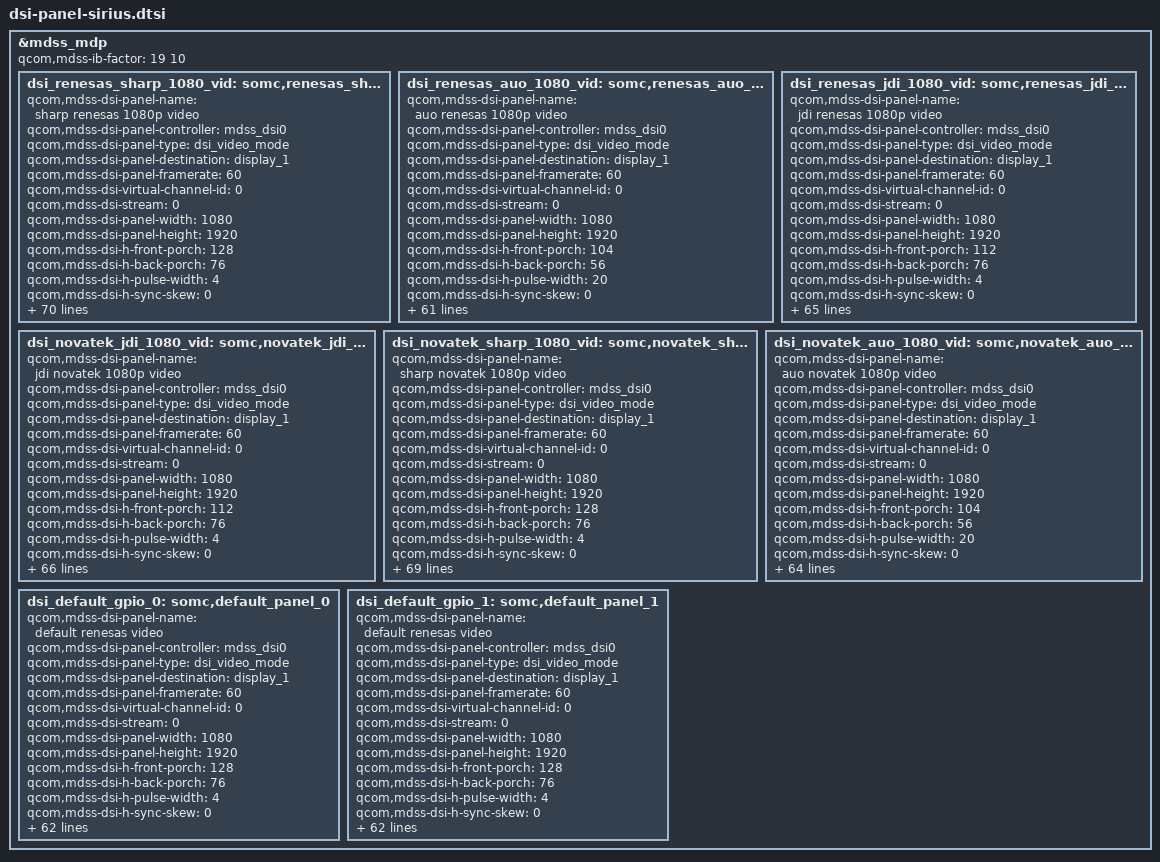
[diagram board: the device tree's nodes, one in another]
/* Copyright (c) 2012, Code Aurora Forum. All rights reserved.
 * Copyright (C) 2012-2014 Sony Mobile Communications AB.
 *
 * This program is free software; you can redistribute it and/or modify
 * it under the terms of the GNU General Public License version 2 and
 * only version 2 as published by the Free Software Foundation.
 *
 * This program is distributed in the hope that it will be useful,
 * but WITHOUT ANY WARRANTY; without even the implied warranty of
 * MERCHANTABILITY or FITNESS FOR A PARTICULAR PURPOSE.  See the
 * GNU General Public License for more details.
 */

&mdss_mdp {
	qcom,mdss-ib-factor = <19 10>;
	dsi_renesas_sharp_1080_vid: somc,renesas_sharp_1080p_panel {
		qcom,mdss-dsi-panel-name = "sharp renesas 1080p video";
		qcom,mdss-dsi-panel-controller = <&mdss_dsi0>;
		qcom,mdss-dsi-panel-type = "dsi_video_mode";
		qcom,mdss-dsi-panel-destination = "display_1";
		qcom,mdss-dsi-panel-framerate = <60>;
		qcom,mdss-dsi-virtual-channel-id = <0>;
		qcom,mdss-dsi-stream = <0>;
		qcom,mdss-dsi-panel-width = <1080>;
		qcom,mdss-dsi-panel-height = <1920>;
		qcom,mdss-dsi-h-front-porch = <128>;
		qcom,mdss-dsi-h-back-porch = <76>;
		qcom,mdss-dsi-h-pulse-width = <4>;
		qcom,mdss-dsi-h-sync-skew = <0>;
		qcom,mdss-dsi-v-back-porch = <3>;
		qcom,mdss-dsi-v-front-porch = <4>;
		qcom,mdss-dsi-v-pulse-width = <2>;
		qcom,mdss-dsi-h-left-border = <0>;
		qcom,mdss-dsi-h-right-border = <0>;
		qcom,mdss-dsi-v-top-border = <0>;
		qcom,mdss-dsi-v-bottom-border = <0>;
		qcom,mdss-dsi-bpp = <24>;
		qcom,mdss-dsi-underflow-color = <0x0>;
		qcom,mdss-dsi-border-color = <0>;
		somc,mdss-dsi-init-command = [23 01 00 00 00 00 02 B0 04
				23 01 00 00 00 00 02 00 00
				23 01 00 00 00 00 02 00 00
				23 01 00 00 00 00 02 D6 01
				29 01 00 00 00 00 03 C0 0F 0F
				29 01 00 00 00 00 03 EC 00 10
				29 01 00 00 00 00 19 C7
					05 19 22 2B 38 51 41 50 5C 64 6B 74
					0F 23 2B 32 3F 52 44 55 61 69 70 77
				29 01 00 00 00 00 19 C8
					03 18 21 2B 38 51 42 4F 5D 65 6C 74
					0D 22 2A 32 3E 52 41 54 5D 66 6D 77
				29 01 00 00 00 00 19 C9
					00 15 1E 28 36 50 42 50 5E 66 6D 74
					0A 1F 27 2F 3D 51 41 55 5E 67 6E 77
				05 01 00 00 00 00 01 11];
		qcom,mdss-dsi-on-command = [05 01 00 00 00 00 01 29];
		qcom,mdss-dsi-off-command = [05 01 00 00 14 00 01 28
				05 01 00 00 6E 00 01 10];
		qcom,mdss-dsi-on-command-state = "dsi_lp_mode";
		qcom,mdss-dsi-off-command-state = "dsi_hs_mode";

		somc,mdss-dsi-cabc-early-on-command = [39 01 00 00 00 00 03 51 0F FF
				15 01 00 00 00 00 02 53 24
				15 01 00 00 00 00 02 55 02];
		somc,mdss-dsi-cabc-late-off-command = [39 01 00 00 00 00 03 51 00 00
				15 01 00 00 00 00 02 55 00
				15 01 00 00 00 00 02 53 20];
		somc,mdss-dsi-cabc-enabled = <0>;

		qcom,mdss-dsi-h-sync-pulse = <1>;
		qcom,mdss-dsi-traffic-mode = "non_burst_sync_event";
		qcom,mdss-dsi-bllp-eof-power-mode;
		qcom,mdss-dsi-bllp-power-mode;
		qcom,mdss-dsi-lane-0-state;
		qcom,mdss-dsi-lane-1-state;
		qcom,mdss-dsi-lane-2-state;
		qcom,mdss-dsi-lane-3-state;
		qcom,mdss-dsi-panel-timings = [E6 38 26 00 68 6C 2A 3A 2C 03 04 00];
		qcom,mdss-dsi-lp11-init;
		qcom,mdss-dsi-t-clk-post = <0x02>;
		qcom,mdss-dsi-t-clk-pre = <0x2B>;
		qcom,mdss-dsi-bl-min-level = <1>;
		qcom,mdss-dsi-bl-max-level = <4095>;
		qcom,mdss-brightness-max-level = <4095>;
		qcom,mdss-dsi-dma-trigger = "trigger_sw";
		qcom,mdss-dsi-mdp-trigger = "none";
		qcom,mdss-dsi-bl-pmic-control-type = "bl_ctrl_wled";
		qcom,mdss-dsi-pan-enable-dynamic-fps;
		qcom,mdss-dsi-pan-fps-update = "dfps_suspend_resume_mode";
		qcom,cont-splash-enabled;

		somc,driver-ic = <0>;
		somc,dric-gpio = <&msmgpio 26 0>;
		somc,mul-channel-scaling = <3>;
		somc,mdss-phy-size-mm = <64 114>;
		somc,mdss-dsi-lane-config = [00 c2 ef 00 00 00 00 01 75
				00 c2 ef 00 00 00 00 01 75
				00 c2 ef 00 00 00 00 01 75
				00 c2 ef 00 00 00 00 01 75
				00 02 45 00 00 00 00 01 97];
		somc,mdss-dsi-disp-on-in-hs = <1>;
		somc,mdss-dsi-wait-time-before-on-cmd = <150>;
		somc,lcd-id = <1>;
		somc,lcd-id-adc = <0 57000>;
		somc,disp-en-on-pre = <25>;
		somc,pw-on-rst-seq = <0 60>, <1 10>;
		somc,disp-en-off-post = <50>;
		somc,pw-off-rst-b-seq = <0 10>;

		somc,mdss-dsi-pre-uv-command = [23 01 00 00 00 00 02 B0 04];
		somc,mdss-dsi-uv-command = [06 01 00 00 00 00 01 DA
					06 01 00 00 00 00 01 DB];
		somc,mdss-dsi-uv-param-type = <4>;
		somc,mdss-dsi-pcc-table-size = <73>;
		somc,mdss-dsi-pcc-table = <
			0x00 0x01 0x10 0x13 0x28 0x2B 0x8000 0x7400 0x8000
			0x00 0x02 0x14 0x17 0x28 0x2B 0x7a80 0x7400 0x7e00
			0x00 0x03 0x18 0x1B 0x28 0x2B 0x7480 0x7380 0x8000
			0x00 0x04 0x1C 0x1F 0x28 0x2B 0x7280 0x7380 0x8000
			0x00 0x05 0x20 0x23 0x28 0x2B 0x6e00 0x7400 0x8000
			0x00 0x06 0x0C 0x0F 0x24 0x27 0x7f80 0x7200 0x7c00
			0x00 0x07 0x10 0x13 0x24 0x27 0x8000 0x7400 0x7d80
			0x00 0x08 0x14 0x17 0x24 0x27 0x7d00 0x7700 0x7e00
			0x00 0x09 0x18 0x1B 0x24 0x27 0x7700 0x7600 0x8000
			0x00 0x0A 0x1C 0x1F 0x24 0x27 0x7380 0x7500 0x7c00
			0x00 0x0B 0x20 0x23 0x24 0x27 0x6f00 0x7500 0x7e80
			0x00 0x0C 0x0C 0x0F 0x20 0x23 0x7f80 0x7200 0x7900
			0x00 0x0D 0x10 0x13 0x20 0x23 0x8000 0x7400 0x7b00
			0x00 0x0E 0x14 0x17 0x20 0x23 0x7a80 0x7400 0x7b00
			0x00 0x0F 0x18 0x1B 0x20 0x23 0x7800 0x7700 0x7e80
			0x00 0x10 0x1C 0x1F 0x20 0x23 0x7780 0x7900 0x7f80
			0x00 0x11 0x20 0x23 0x20 0x23 0x7300 0x7900 0x7f00
			0x00 0x12 0x24 0x27 0x20 0x23 0x7100 0x7980 0x8000
			0x00 0x13 0x0C 0x0F 0x1C 0x1F 0x7f80 0x7200 0x7700
			0x00 0x14 0x10 0x13 0x1C 0x1F 0x7c00 0x7000 0x7580
			0x00 0x15 0x14 0x17 0x1C 0x1F 0x7f80 0x7900 0x7e00
			0x00 0x16 0x18 0x1B 0x1C 0x1F 0x7c00 0x7a00 0x7d80
			0x00 0x17 0x1C 0x1F 0x1C 0x1F 0x7900 0x7a00 0x7e00
			0x00 0x18 0x20 0x23 0x1C 0x1F 0x7600 0x7c80 0x8000
			0x00 0x19 0x24 0x27 0x1C 0x1F 0x7300 0x7c00 0x7e80
			0x00 0x1A 0x0C 0x0F 0x18 0x1B 0x8000 0x7200 0x7300
			0x00 0x1B 0x10 0x13 0x18 0x1B 0x7e80 0x7200 0x7500
			0x00 0x1C 0x14 0x17 0x18 0x1B 0x7f00 0x7900 0x7b80
			0x00 0x1D 0x18 0x1B 0x18 0x1B 0x7f00 0x7d00 0x7e00
			0x00 0x1E 0x1C 0x1F 0x18 0x1B 0x7d00 0x7d80 0x8000
			0x00 0x1F 0x20 0x23 0x18 0x1B 0x7900 0x7f00 0x8000
			0x00 0x20 0x24 0x27 0x18 0x1B 0x7780 0x8000 0x8000
			0x00 0x21 0x10 0x13 0x14 0x17 0x7f80 0x7380 0x7200
			0x00 0x22 0x14 0x17 0x14 0x17 0x7f00 0x7900 0x7900
			0x00 0x23 0x18 0x1B 0x14 0x17 0x7f00 0x7d00 0x7b80
			0xFF 0x00 0x1C 0x1F 0x14 0x17 0x8000 0x8000 0x8000
			0x00 0x24 0x20 0x23 0x14 0x17 0x7a00 0x8000 0x7e80
			0x00 0x25 0x24 0x27 0x14 0x17 0x7780 0x8000 0x7d80
			0x00 0x26 0x10 0x13 0x10 0x13 0x8000 0x7400 0x7000
			0x00 0x27 0x14 0x17 0x10 0x13 0x7f80 0x7900 0x7680
			0x00 0x28 0x18 0x1B 0x10 0x13 0x8000 0x7d80 0x7980
			0x00 0x29 0x1C 0x1F 0x10 0x13 0x8000 0x8000 0x7c00
			0x00 0x2A 0x20 0x23 0x10 0x13 0x7a00 0x8000 0x7c00
			0x00 0x2B 0x10 0x13 0x0C 0x0F 0x7f80 0x7480 0x6f00
			0x00 0x2C 0x14 0x17 0x0C 0x0F 0x7f80 0x7900 0x7400
			0x00 0x2D 0x18 0x1B 0x0C 0x0F 0x7f80 0x7d80 0x7680
			0x00 0x2E 0x1C 0x1F 0x0C 0x0F 0x8000 0x8000 0x7980
			0x01 0x00 0x00 0x09 0x32 0x3B 0x8000 0x6D00 0x8000
			0x02 0x00 0x0A 0x13 0x32 0x3B 0x7A00 0x7100 0x8000
			0x03 0x00 0x14 0x1D 0x32 0x3B 0x7400 0x7180 0x8000
			0x04 0x00 0x1E 0x27 0x32 0x3B 0x7100 0x7200 0x8000
			0x05 0x00 0x28 0x31 0x32 0x3B 0x6C80 0x7180 0x8000
			0x06 0x00 0x32 0x3B 0x32 0x3B 0x6680 0x7300 0x8000
			0x07 0x00 0x00 0x09 0x28 0x31 0x8000 0x6B80 0x7080
			0x08 0x00 0x0A 0x13 0x28 0x31 0x8000 0x7400 0x8000
			0x09 0x00 0x14 0x1D 0x28 0x31 0x7A00 0x7700 0x8000
			0x0A 0x00 0x1E 0x27 0x28 0x31 0x7600 0x7780 0x8000
			0x0B 0x00 0x28 0x31 0x28 0x31 0x6F80 0x7980 0x8000
			0x0C 0x00 0x32 0x3B 0x28 0x31 0x7080 0x7E80 0x8000
			0x0D 0x00 0x00 0x09 0x14 0x27 0x8000 0x6B00 0x6D00
			0x0E 0x00 0x0A 0x13 0x14 0x27 0x8000 0x7380 0x7480
			0xFF 0x00 0x14 0x27 0x14 0x27 0x8000 0x8000 0x8000
			0x10 0x00 0x28 0x31 0x14 0x27 0x7500 0x8000 0x7E80
			0x11 0x00 0x32 0x3B 0x14 0x27 0x7100 0x8000 0x7C80
			0x12 0x00 0x00 0x09 0x00 0x09 0x8000 0x6900 0x6500
			0x13 0x00 0x00 0x13 0x0A 0x13 0x8000 0x7300 0x6F00
			0x13 0x00 0x0A 0x13 0x00 0x09 0x8000 0x7300 0x6F00
			0x14 0x00 0x14 0x27 0x0A 0x13 0x7F00 0x8000 0x7900
			0x15 0x00 0x14 0x27 0x00 0x09 0x7E80 0x8000 0x7680
			0x16 0x00 0x28 0x31 0x0A 0x13 0x7380 0x8000 0x7600
			0x17 0x00 0x32 0x3B 0x0A 0x13 0x7080 0x8000 0x7900
			0x18 0x00 0x28 0x31 0x00 0x09 0x7A00 0x8000 0x7580
			0x19 0x00 0x32 0x3B 0x00 0x09 0x6F00 0x8000 0x7200>;
	};

	dsi_renesas_auo_1080_vid: somc,renesas_auo_1080p_panel {
		qcom,mdss-dsi-panel-name = "auo renesas 1080p video";
		qcom,mdss-dsi-panel-controller = <&mdss_dsi0>;
		qcom,mdss-dsi-panel-type = "dsi_video_mode";
		qcom,mdss-dsi-panel-destination = "display_1";
		qcom,mdss-dsi-panel-framerate = <60>;
		qcom,mdss-dsi-virtual-channel-id = <0>;
		qcom,mdss-dsi-stream = <0>;
		qcom,mdss-dsi-panel-width = <1080>;
		qcom,mdss-dsi-panel-height = <1920>;
		qcom,mdss-dsi-h-front-porch = <104>;
		qcom,mdss-dsi-h-back-porch = <56>;
		qcom,mdss-dsi-h-pulse-width = <20>;
		qcom,mdss-dsi-h-sync-skew = <0>;
		qcom,mdss-dsi-v-back-porch = <20>;
		qcom,mdss-dsi-v-front-porch = <24>;
		qcom,mdss-dsi-v-pulse-width = <10>;
		qcom,mdss-dsi-h-left-border = <0>;
		qcom,mdss-dsi-h-right-border = <0>;
		qcom,mdss-dsi-v-top-border = <0>;
		qcom,mdss-dsi-v-bottom-border = <0>;
		qcom,mdss-dsi-bpp = <24>;
		qcom,mdss-dsi-underflow-color = <0x0>;
		qcom,mdss-dsi-border-color = <0>;
		somc,mdss-dsi-init-command = [15 01 00 00 00 00 02 35 01
				29 01 00 00 00 00 02 B0 04
				29 01 00 00 00 00 08 C2 30 F7 84 1B 0C 00 00
				29 01 00 00 00 00 02 D6 01
				05 01 00 00 00 00 01 29];
		qcom,mdss-dsi-on-command = [05 01 00 00 78 00 01 11];
		qcom,mdss-dsi-off-command = [05 01 00 00 00 00 01 28
				05 01 00 00 43 00 01 10];
		qcom,mdss-dsi-on-command-state = "dsi_lp_mode";
		qcom,mdss-dsi-off-command-state = "dsi_hs_mode";
		qcom,mdss-dsi-h-sync-pulse = <1>;
		qcom,mdss-dsi-traffic-mode = "non_burst_sync_event";
		qcom,mdss-dsi-bllp-eof-power-mode;
		qcom,mdss-dsi-bllp-power-mode;
		qcom,mdss-dsi-lane-0-state;
		qcom,mdss-dsi-lane-1-state;
		qcom,mdss-dsi-lane-2-state;
		qcom,mdss-dsi-lane-3-state;
		qcom,mdss-dsi-panel-timings = [E6 38 26 00 68 6C 2A 3C 2C 03 04 00];
		qcom,mdss-dsi-t-clk-post = <0x02>;
		qcom,mdss-dsi-t-clk-pre = <0x2B>;
		qcom,mdss-dsi-bl-min-level = <1>;
		qcom,mdss-dsi-bl-max-level = <4095>;
		qcom,mdss-brightness-max-level = <4095>;
		qcom,mdss-dsi-dma-trigger = "trigger_sw";
		qcom,mdss-dsi-mdp-trigger = "none";
		qcom,mdss-dsi-bl-pmic-control-type = "bl_ctrl_wled";
		qcom,mdss-dsi-pan-enable-dynamic-fps;
		qcom,mdss-dsi-pan-fps-update = "dfps_suspend_resume_mode";
		qcom,cont-splash-enabled;

		somc,driver-ic = <0>;
		somc,dric-gpio = <&msmgpio 26 0>;
		somc,mul-channel-scaling = <3>;
		somc,mdss-phy-size-mm = <64 114>;
		somc,mdss-dsi-lane-config = [00 c2 ef 00 00 00 00 01 75
				00 c2 ef 00 00 00 00 01 75
				00 c2 ef 00 00 00 00 01 75
				00 c2 ef 00 00 00 00 01 75
				00 02 45 00 00 00 00 01 97];
		somc,mdss-dsi-disp-on-in-hs = <1>;
		somc,lcd-id = <1>;
		somc,lcd-id-adc = <215000 256000>;
		somc,pw-on-rst-seq = <1 10>, <0 1>, <1 10>;
		somc,pw-off-rst-seq = <0 0>;

		somc,mdss-dsi-pre-uv-command = [23 01 00 00 00 00 02 B0 04];
		somc,mdss-dsi-uv-command = [06 01 00 00 00 00 01 DA
					06 01 00 00 00 00 01 DC];
		somc,mdss-dsi-uv-param-type = <4>;
		somc,mdss-dsi-pcc-table-size = <73>;
		somc,mdss-dsi-pcc-table = <
			0x00 0x01 0x10 0x13 0x28 0x2B 0x8000 0x7400 0x8000
			0x00 0x02 0x14 0x17 0x28 0x2B 0x7a80 0x7400 0x7e00
			0x00 0x03 0x18 0x1B 0x28 0x2B 0x7480 0x7380 0x8000
			0x00 0x04 0x1C 0x1F 0x28 0x2B 0x7280 0x7380 0x8000
			0x00 0x05 0x20 0x23 0x28 0x2B 0x6e00 0x7400 0x8000
			0x00 0x06 0x0C 0x0F 0x24 0x27 0x7f80 0x7200 0x7c00
			0x00 0x07 0x10 0x13 0x24 0x27 0x8000 0x7400 0x7d80
			0x00 0x08 0x14 0x17 0x24 0x27 0x7d00 0x7700 0x7e00
			0x00 0x09 0x18 0x1B 0x24 0x27 0x7700 0x7600 0x8000
			0x00 0x0A 0x1C 0x1F 0x24 0x27 0x7380 0x7500 0x7c00
			0x00 0x0B 0x20 0x23 0x24 0x27 0x6f00 0x7500 0x7e80
			0x00 0x0C 0x0C 0x0F 0x20 0x23 0x7f80 0x7200 0x7900
			0x00 0x0D 0x10 0x13 0x20 0x23 0x8000 0x7400 0x7b00
			0x00 0x0E 0x14 0x17 0x20 0x23 0x7a80 0x7400 0x7b00
			0x00 0x0F 0x18 0x1B 0x20 0x23 0x7800 0x7700 0x7e80
			0x00 0x10 0x1C 0x1F 0x20 0x23 0x7780 0x7900 0x7f80
			0x00 0x11 0x20 0x23 0x20 0x23 0x7300 0x7900 0x7f00
			0x00 0x12 0x24 0x27 0x20 0x23 0x7100 0x7980 0x8000
			0x00 0x13 0x0C 0x0F 0x1C 0x1F 0x7f80 0x7200 0x7700
			0x00 0x14 0x10 0x13 0x1C 0x1F 0x7c00 0x7000 0x7580
			0x00 0x15 0x14 0x17 0x1C 0x1F 0x7f80 0x7900 0x7e00
			0x00 0x16 0x18 0x1B 0x1C 0x1F 0x7c00 0x7a00 0x7d80
			0x00 0x17 0x1C 0x1F 0x1C 0x1F 0x7900 0x7a00 0x7e00
			0x00 0x18 0x20 0x23 0x1C 0x1F 0x7600 0x7c80 0x8000
			0x00 0x19 0x24 0x27 0x1C 0x1F 0x7300 0x7c00 0x7e80
			0x00 0x1A 0x0C 0x0F 0x18 0x1B 0x8000 0x7200 0x7300
			0x00 0x1B 0x10 0x13 0x18 0x1B 0x7e80 0x7200 0x7500
			0x00 0x1C 0x14 0x17 0x18 0x1B 0x7f00 0x7900 0x7b80
			0x00 0x1D 0x18 0x1B 0x18 0x1B 0x7f00 0x7d00 0x7e00
			0x00 0x1E 0x1C 0x1F 0x18 0x1B 0x7d00 0x7d80 0x8000
			0x00 0x1F 0x20 0x23 0x18 0x1B 0x7900 0x7f00 0x8000
			0x00 0x20 0x24 0x27 0x18 0x1B 0x7780 0x8000 0x8000
			0x00 0x21 0x10 0x13 0x14 0x17 0x7f80 0x7380 0x7200
			0x00 0x22 0x14 0x17 0x14 0x17 0x7f00 0x7900 0x7900
			0x00 0x23 0x18 0x1B 0x14 0x17 0x7f00 0x7d00 0x7b80
			0xFF 0x00 0x1C 0x1F 0x14 0x17 0x8000 0x8000 0x8000
			0x00 0x24 0x20 0x23 0x14 0x17 0x7a00 0x8000 0x7e80
			0x00 0x25 0x24 0x27 0x14 0x17 0x7780 0x8000 0x7d80
			0x00 0x26 0x10 0x13 0x10 0x13 0x8000 0x7400 0x7000
			0x00 0x27 0x14 0x17 0x10 0x13 0x7f80 0x7900 0x7680
			0x00 0x28 0x18 0x1B 0x10 0x13 0x8000 0x7d80 0x7980
			0x00 0x29 0x1C 0x1F 0x10 0x13 0x8000 0x8000 0x7c00
			0x00 0x2A 0x20 0x23 0x10 0x13 0x7a00 0x8000 0x7c00
			0x00 0x2B 0x10 0x13 0x0C 0x0F 0x7f80 0x7480 0x6f00
			0x00 0x2C 0x14 0x17 0x0C 0x0F 0x7f80 0x7900 0x7400
			0x00 0x2D 0x18 0x1B 0x0C 0x0F 0x7f80 0x7d80 0x7680
			0x00 0x2E 0x1C 0x1F 0x0C 0x0F 0x8000 0x8000 0x7980
			0x01 0x00 0x00 0x09 0x32 0x3B 0x8000 0x6D00 0x8000
			0x02 0x00 0x0A 0x13 0x32 0x3B 0x7A00 0x7100 0x8000
			0x03 0x00 0x14 0x1D 0x32 0x3B 0x7400 0x7180 0x8000
			0x04 0x00 0x1E 0x27 0x32 0x3B 0x7100 0x7200 0x8000
			0x05 0x00 0x28 0x31 0x32 0x3B 0x6C80 0x7180 0x8000
			0x06 0x00 0x32 0x3B 0x32 0x3B 0x6680 0x7300 0x8000
			0x07 0x00 0x00 0x09 0x28 0x31 0x8000 0x6B80 0x7080
			0x08 0x00 0x0A 0x13 0x28 0x31 0x8000 0x7400 0x8000
			0x09 0x00 0x14 0x1D 0x28 0x31 0x7A00 0x7700 0x8000
			0x0A 0x00 0x1E 0x27 0x28 0x31 0x7600 0x7780 0x8000
			0x0B 0x00 0x28 0x31 0x28 0x31 0x6F80 0x7980 0x8000
			0x0C 0x00 0x32 0x3B 0x28 0x31 0x7080 0x7E80 0x8000
			0x0D 0x00 0x00 0x09 0x14 0x27 0x8000 0x6B00 0x6D00
			0x0E 0x00 0x0A 0x13 0x14 0x27 0x8000 0x7380 0x7480
			0xFF 0x00 0x14 0x27 0x14 0x27 0x8000 0x8000 0x8000
			0x10 0x00 0x28 0x31 0x14 0x27 0x7500 0x8000 0x7E80
			0x11 0x00 0x32 0x3B 0x14 0x27 0x7100 0x8000 0x7C80
			0x12 0x00 0x00 0x09 0x00 0x09 0x8000 0x6900 0x6500
			0x13 0x00 0x00 0x13 0x0A 0x13 0x8000 0x7300 0x6F00
			0x13 0x00 0x0A 0x13 0x00 0x09 0x8000 0x7300 0x6F00
			0x14 0x00 0x14 0x27 0x0A 0x13 0x7F00 0x8000 0x7900
			0x15 0x00 0x14 0x27 0x00 0x09 0x7E80 0x8000 0x7680
			0x16 0x00 0x28 0x31 0x0A 0x13 0x7380 0x8000 0x7600
			0x17 0x00 0x32 0x3B 0x0A 0x13 0x7080 0x8000 0x7900
			0x18 0x00 0x28 0x31 0x00 0x09 0x7A00 0x8000 0x7580
			0x19 0x00 0x32 0x3B 0x00 0x09 0x6F00 0x8000 0x7200>;
	};

	dsi_renesas_jdi_1080_vid: somc,renesas_jdi_1080p_panel {
		qcom,mdss-dsi-panel-name = "jdi renesas 1080p video";
		qcom,mdss-dsi-panel-controller = <&mdss_dsi0>;
		qcom,mdss-dsi-panel-type = "dsi_video_mode";
		qcom,mdss-dsi-panel-destination = "display_1";
		qcom,mdss-dsi-panel-framerate = <60>;
		qcom,mdss-dsi-virtual-channel-id = <0>;
		qcom,mdss-dsi-stream = <0>;
		qcom,mdss-dsi-panel-width = <1080>;
		qcom,mdss-dsi-panel-height = <1920>;
		qcom,mdss-dsi-h-front-porch = <112>;
		qcom,mdss-dsi-h-back-porch = <76>;
		qcom,mdss-dsi-h-pulse-width = <4>;
		qcom,mdss-dsi-h-sync-skew = <0>;
		qcom,mdss-dsi-v-back-porch = <4>;
		qcom,mdss-dsi-v-front-porch = <27>;
		qcom,mdss-dsi-v-pulse-width = <4>;
		qcom,mdss-dsi-h-left-border = <0>;
		qcom,mdss-dsi-h-right-border = <0>;
		qcom,mdss-dsi-v-top-border = <0>;
		qcom,mdss-dsi-v-bottom-border = <0>;
		qcom,mdss-dsi-bpp = <24>;
		qcom,mdss-dsi-underflow-color = <0x0>;
		qcom,mdss-dsi-border-color = <0>;
		somc,mdss-dsi-init-command = [05 01 00 00 05 00 01 01
				23 01 00 00 00 00 02 B0 00
				23 01 00 00 00 00 02 00 00
				23 01 00 00 00 00 02 00 00
				29 01 00 00 00 00 19 C7
					08 12 1B 24 31 48 40 52 5E 61 6A 76
					08 12 1B 24 31 48 40 52 5E 61 6A 76
				29 01 00 00 00 00 19 C8
					08 12 1B 24 31 49 41 53 5E 61 6A 76
					08 12 1B 24 31 49 41 53 5E 61 6A 76
				29 01 00 00 00 00 19 C9
					08 12 1B 24 31 47 3F 52 5E 61 6A 76
					08 12 1B 24 31 47 3F 52 5E 61 6A 76
				29 01 00 00 00 00 1B D3
					1B 33 BB CC C4 33 33 33 00 01 00 A0 D8
					A0 06 2B 33 33 22 70 02 2B 43 3D BF 99
				23 01 00 00 00 00 02 D6 01];
		qcom,mdss-dsi-on-command = [05 01 00 00 78 00 01 11
				05 01 00 00 00 00 01 29];
		qcom,mdss-dsi-off-command = [05 01 00 00 14 00 01 28
				05 01 00 00 50 00 01 10];
		qcom,mdss-dsi-on-command-state = "dsi_lp_mode";
		qcom,mdss-dsi-off-command-state = "dsi_hs_mode";
		qcom,mdss-dsi-h-sync-pulse = <1>;
		qcom,mdss-dsi-traffic-mode = "non_burst_sync_event";
		qcom,mdss-dsi-bllp-eof-power-mode;
		qcom,mdss-dsi-bllp-power-mode;
		qcom,mdss-dsi-lane-0-state;
		qcom,mdss-dsi-lane-1-state;
		qcom,mdss-dsi-lane-2-state;
		qcom,mdss-dsi-lane-3-state;
		qcom,mdss-dsi-panel-timings = [E6 38 26 00 68 6C 2A 3C 2C 03 04 00];
		qcom,mdss-dsi-lp11-init;
		qcom,mdss-dsi-t-clk-post = <0x02>;
		qcom,mdss-dsi-t-clk-pre = <0x2B>;
		qcom,mdss-dsi-bl-min-level = <1>;
		qcom,mdss-dsi-bl-max-level = <4095>;
		qcom,mdss-brightness-max-level = <4095>;
		qcom,mdss-dsi-dma-trigger = "trigger_sw";
		qcom,mdss-dsi-mdp-trigger = "none";
		qcom,mdss-dsi-bl-pmic-control-type = "bl_ctrl_wled";
		qcom,mdss-dsi-pan-enable-dynamic-fps;
		qcom,mdss-dsi-pan-fps-update = "dfps_suspend_resume_mode";
		qcom,cont-splash-enabled;

		somc,driver-ic = <0>;
		somc,dric-gpio = <&msmgpio 26 0>;
		somc,mul-channel-scaling = <3>;
		somc,mdss-phy-size-mm = <64 114>;
		somc,mdss-dsi-lane-config = [00 c2 ef 00 00 00 00 01 75
				00 c2 ef 00 00 00 00 01 75
				00 c2 ef 00 00 00 00 01 75
				00 c2 ef 00 00 00 00 01 75
				00 02 45 00 00 00 00 01 97];
		somc,mdss-dsi-disp-on-in-hs = <1>;
		somc,lcd-id = <1>;
		somc,lcd-id-adc = <353000 414000>;
		somc,disp-en-on-pre = <5>;
		somc,disp-en-on-post = <15>;
		somc,disp-en-off-post = <70>;
		somc,pw-on-rst-seq = <1 10>;
		somc,pw-off-rst-seq = <0 0>;

		somc,mdss-dsi-pre-uv-command = [23 01 00 00 00 00 02 B0 04];
		somc,mdss-dsi-uv-command = [06 01 00 00 00 00 01 DA
					06 01 00 00 00 00 01 DB];
		somc,mdss-dsi-uv-param-type = <4>;
		somc,mdss-dsi-pcc-table-size = <73>;
		somc,mdss-dsi-pcc-table = <
			0x00 0x01 0x10 0x13 0x28 0x2B 0x8000 0x7400 0x8000
			0x00 0x02 0x14 0x17 0x28 0x2B 0x7a80 0x7400 0x7e00
			0x00 0x03 0x18 0x1B 0x28 0x2B 0x7480 0x7380 0x8000
			0x00 0x04 0x1C 0x1F 0x28 0x2B 0x7280 0x7380 0x8000
			0x00 0x05 0x20 0x23 0x28 0x2B 0x6e00 0x7400 0x8000
			0x00 0x06 0x0C 0x0F 0x24 0x27 0x7f80 0x7200 0x7c00
			0x00 0x07 0x10 0x13 0x24 0x27 0x8000 0x7400 0x7d80
			0x00 0x08 0x14 0x17 0x24 0x27 0x7d00 0x7700 0x7e00
			0x00 0x09 0x18 0x1B 0x24 0x27 0x7700 0x7600 0x8000
			0x00 0x0A 0x1C 0x1F 0x24 0x27 0x7380 0x7500 0x7c00
			0x00 0x0B 0x20 0x23 0x24 0x27 0x6f00 0x7500 0x7e80
			0x00 0x0C 0x0C 0x0F 0x20 0x23 0x7f80 0x7200 0x7900
			0x00 0x0D 0x10 0x13 0x20 0x23 0x8000 0x7400 0x7b00
			0x00 0x0E 0x14 0x17 0x20 0x23 0x7a80 0x7400 0x7b00
			0x00 0x0F 0x18 0x1B 0x20 0x23 0x7800 0x7700 0x7e80
			0x00 0x10 0x1C 0x1F 0x20 0x23 0x7780 0x7900 0x7f80
			0x00 0x11 0x20 0x23 0x20 0x23 0x7300 0x7900 0x7f00
			0x00 0x12 0x24 0x27 0x20 0x23 0x7100 0x7980 0x8000
			0x00 0x13 0x0C 0x0F 0x1C 0x1F 0x7f80 0x7200 0x7700
			0x00 0x14 0x10 0x13 0x1C 0x1F 0x7c00 0x7000 0x7580
			0x00 0x15 0x14 0x17 0x1C 0x1F 0x7f80 0x7900 0x7e00
			0x00 0x16 0x18 0x1B 0x1C 0x1F 0x7c00 0x7a00 0x7d80
			0x00 0x17 0x1C 0x1F 0x1C 0x1F 0x7900 0x7a00 0x7e00
			0x00 0x18 0x20 0x23 0x1C 0x1F 0x7600 0x7c80 0x8000
			0x00 0x19 0x24 0x27 0x1C 0x1F 0x7300 0x7c00 0x7e80
			0x00 0x1A 0x0C 0x0F 0x18 0x1B 0x8000 0x7200 0x7300
			0x00 0x1B 0x10 0x13 0x18 0x1B 0x7e80 0x7200 0x7500
			0x00 0x1C 0x14 0x17 0x18 0x1B 0x7f00 0x7900 0x7b80
			0x00 0x1D 0x18 0x1B 0x18 0x1B 0x7f00 0x7d00 0x7e00
			0x00 0x1E 0x1C 0x1F 0x18 0x1B 0x7d00 0x7d80 0x8000
			0x00 0x1F 0x20 0x23 0x18 0x1B 0x7900 0x7f00 0x8000
			0x00 0x20 0x24 0x27 0x18 0x1B 0x7780 0x8000 0x8000
			0x00 0x21 0x10 0x13 0x14 0x17 0x7f80 0x7380 0x7200
			0x00 0x22 0x14 0x17 0x14 0x17 0x7f00 0x7900 0x7900
			0x00 0x23 0x18 0x1B 0x14 0x17 0x7f00 0x7d00 0x7b80
			0xFF 0x00 0x1C 0x1F 0x14 0x17 0x8000 0x8000 0x8000
			0x00 0x24 0x20 0x23 0x14 0x17 0x7a00 0x8000 0x7e80
			0x00 0x25 0x24 0x27 0x14 0x17 0x7780 0x8000 0x7d80
			0x00 0x26 0x10 0x13 0x10 0x13 0x8000 0x7400 0x7000
			0x00 0x27 0x14 0x17 0x10 0x13 0x7f80 0x7900 0x7680
			0x00 0x28 0x18 0x1B 0x10 0x13 0x8000 0x7d80 0x7980
			0x00 0x29 0x1C 0x1F 0x10 0x13 0x8000 0x8000 0x7c00
			0x00 0x2A 0x20 0x23 0x10 0x13 0x7a00 0x8000 0x7c00
			0x00 0x2B 0x10 0x13 0x0C 0x0F 0x7f80 0x7480 0x6f00
			0x00 0x2C 0x14 0x17 0x0C 0x0F 0x7f80 0x7900 0x7400
			0x00 0x2D 0x18 0x1B 0x0C 0x0F 0x7f80 0x7d80 0x7680
			0x00 0x2E 0x1C 0x1F 0x0C 0x0F 0x8000 0x8000 0x7980
			0x01 0x00 0x00 0x09 0x32 0x3B 0x8000 0x6D00 0x8000
			0x02 0x00 0x0A 0x13 0x32 0x3B 0x7A00 0x7100 0x8000
			0x03 0x00 0x14 0x1D 0x32 0x3B 0x7400 0x7180 0x8000
			0x04 0x00 0x1E 0x27 0x32 0x3B 0x7100 0x7200 0x8000
			0x05 0x00 0x28 0x31 0x32 0x3B 0x6C80 0x7180 0x8000
			0x06 0x00 0x32 0x3B 0x32 0x3B 0x6680 0x7300 0x8000
			0x07 0x00 0x00 0x09 0x28 0x31 0x8000 0x6B80 0x7080
			0x08 0x00 0x0A 0x13 0x28 0x31 0x8000 0x7400 0x8000
			0x09 0x00 0x14 0x1D 0x28 0x31 0x7A00 0x7700 0x8000
			0x0A 0x00 0x1E 0x27 0x28 0x31 0x7600 0x7780 0x8000
			0x0B 0x00 0x28 0x31 0x28 0x31 0x6F80 0x7980 0x8000
			0x0C 0x00 0x32 0x3B 0x28 0x31 0x7080 0x7E80 0x8000
			0x0D 0x00 0x00 0x09 0x14 0x27 0x8000 0x6B00 0x6D00
			0x0E 0x00 0x0A 0x13 0x14 0x27 0x8000 0x7380 0x7480
			0xFF 0x00 0x14 0x27 0x14 0x27 0x8000 0x8000 0x8000
			0x10 0x00 0x28 0x31 0x14 0x27 0x7500 0x8000 0x7E80
			0x11 0x00 0x32 0x3B 0x14 0x27 0x7100 0x8000 0x7C80
			0x12 0x00 0x00 0x09 0x00 0x09 0x8000 0x6900 0x6500
			0x13 0x00 0x00 0x13 0x0A 0x13 0x8000 0x7300 0x6F00
			0x13 0x00 0x0A 0x13 0x00 0x09 0x8000 0x7300 0x6F00
			0x14 0x00 0x14 0x27 0x0A 0x13 0x7F00 0x8000 0x7900
			0x15 0x00 0x14 0x27 0x00 0x09 0x7E80 0x8000 0x7680
			0x16 0x00 0x28 0x31 0x0A 0x13 0x7380 0x8000 0x7600
			0x17 0x00 0x32 0x3B 0x0A 0x13 0x7080 0x8000 0x7900
			0x18 0x00 0x28 0x31 0x00 0x09 0x7A00 0x8000 0x7580
			0x19 0x00 0x32 0x3B 0x00 0x09 0x6F00 0x8000 0x7200>;
	};

	dsi_novatek_jdi_1080_vid: somc,novatek_jdi_1080p_panel {
		qcom,mdss-dsi-panel-name = "jdi novatek 1080p video";
		qcom,mdss-dsi-panel-controller = <&mdss_dsi0>;
		qcom,mdss-dsi-panel-type = "dsi_video_mode";
		qcom,mdss-dsi-panel-destination = "display_1";
		qcom,mdss-dsi-panel-framerate = <60>;
		qcom,mdss-dsi-virtual-channel-id = <0>;
		qcom,mdss-dsi-stream = <0>;
		qcom,mdss-dsi-panel-width = <1080>;
		qcom,mdss-dsi-panel-height = <1920>;
		qcom,mdss-dsi-h-front-porch = <112>;
		qcom,mdss-dsi-h-back-porch = <76>;
		qcom,mdss-dsi-h-pulse-width = <4>;
		qcom,mdss-dsi-h-sync-skew = <0>;
		qcom,mdss-dsi-v-back-porch = <4>;
		qcom,mdss-dsi-v-front-porch = <27>;
		qcom,mdss-dsi-v-pulse-width = <4>;
		qcom,mdss-dsi-h-left-border = <0>;
		qcom,mdss-dsi-h-right-border = <0>;
		qcom,mdss-dsi-v-top-border = <0>;
		qcom,mdss-dsi-v-bottom-border = <0>;
		qcom,mdss-dsi-bpp = <24>;
		qcom,mdss-dsi-underflow-color = <0x0>;
		qcom,mdss-dsi-border-color = <0>;
		somc,mdss-dsi-init-command = [05 01 00 00 0A 00 01 01
				23 01 00 00 00 00 02 FF 01
				23 01 00 00 00 00 02 75 00
				23 01 00 00 00 00 02 76 30
				23 01 00 00 00 00 02 77 00
				23 01 00 00 00 00 02 78 43
				23 01 00 00 00 00 02 79 00
				23 01 00 00 00 00 02 7A 61
				23 01 00 00 00 00 02 7B 00
				23 01 00 00 00 00 02 7C 7D
				23 01 00 00 00 00 02 7D 00
				23 01 00 00 00 00 02 7E 98
				23 01 00 00 00 00 02 7F 00
				23 01 00 00 00 00 02 80 AE
				23 01 00 00 00 00 02 81 00
				23 01 00 00 00 00 02 82 C0
				23 01 00 00 00 00 02 83 00
				23 01 00 00 00 00 02 84 CD
				23 01 00 00 00 00 02 85 00
				23 01 00 00 00 00 02 86 DB
				23 01 00 00 00 00 02 87 01
				23 01 00 00 00 00 02 88 0A
				23 01 00 00 00 00 02 89 01
				23 01 00 00 00 00 02 8A 2A
				23 01 00 00 00 00 02 8B 01
				23 01 00 00 00 00 02 8C 66
				23 01 00 00 00 00 02 8D 01
				23 01 00 00 00 00 02 8E 95
				23 01 00 00 00 00 02 8F 01
				23 01 00 00 00 00 02 90 D8
				23 01 00 00 00 00 02 91 02
				23 01 00 00 00 00 02 92 1A
				23 01 00 00 00 00 02 93 02
				23 01 00 00 00 00 02 94 1C
				23 01 00 00 00 00 02 95 02
				23 01 00 00 00 00 02 96 5E
				23 01 00 00 00 00 02 97 02
				23 01 00 00 00 00 02 98 9A
				23 01 00 00 00 00 02 99 02
				23 01 00 00 00 00 02 9A BF
				23 01 00 00 00 00 02 9B 02
				23 01 00 00 00 00 02 9C ED
				23 01 00 00 00 00 02 9D 03
				23 01 00 00 00 00 02 9E 0B
				23 01 00 00 00 00 02 9F 03
				23 01 00 00 00 00 02 A0 36
				23 01 00 00 00 00 02 A2 03
				23 01 00 00 00 00 02 A3 3B
				23 01 00 00 00 00 02 A4 03
				23 01 00 00 00 00 02 A5 40
				23 01 00 00 00 00 02 A6 03
				23 01 00 00 00 00 02 A7 45
				23 01 00 00 00 00 02 A9 03
				23 01 00 00 00 00 02 AA 54
				23 01 00 00 00 00 02 AB 03
				23 01 00 00 00 00 02 AC 70
				23 01 00 00 00 00 02 AD 03
				23 01 00 00 00 00 02 AE 8E
				23 01 00 00 00 00 02 AF 03
				23 01 00 00 00 00 02 B0 B2
				23 01 00 00 00 00 02 B1 03
				23 01 00 00 00 00 02 B2 C9
				23 01 00 00 00 00 02 B3 00
				23 01 00 00 00 00 02 B4 30
				23 01 00 00 00 00 02 B5 00
				23 01 00 00 00 00 02 B6 43
				23 01 00 00 00 00 02 B7 00
				23 01 00 00 00 00 02 B8 61
				23 01 00 00 00 00 02 B9 00
				23 01 00 00 00 00 02 BA 7D
				23 01 00 00 00 00 02 BB 00
				23 01 00 00 00 00 02 BC 98
				23 01 00 00 00 00 02 BD 00
				23 01 00 00 00 00 02 BE AE
				23 01 00 00 00 00 02 BF 00
				23 01 00 00 00 00 02 C0 C0
				23 01 00 00 00 00 02 C1 00
				23 01 00 00 00 00 02 C2 CD
				23 01 00 00 00 00 02 C3 00
				23 01 00 00 00 00 02 C4 DB
				23 01 00 00 00 00 02 C5 01
				23 01 00 00 00 00 02 C6 0A
				23 01 00 00 00 00 02 C7 01
				23 01 00 00 00 00 02 C8 2A
				23 01 00 00 00 00 02 C9 01
				23 01 00 00 00 00 02 CA 66
				23 01 00 00 00 00 02 CB 01
				23 01 00 00 00 00 02 CC 95
				23 01 00 00 00 00 02 CD 01
				23 01 00 00 00 00 02 CE D8
				23 01 00 00 00 00 02 CF 02
				23 01 00 00 00 00 02 D0 1A
				23 01 00 00 00 00 02 D1 02
				23 01 00 00 00 00 02 D2 1C
				23 01 00 00 00 00 02 D3 02
				23 01 00 00 00 00 02 D4 5E
				23 01 00 00 00 00 02 D5 02
				23 01 00 00 00 00 02 D6 9A
				23 01 00 00 00 00 02 D7 02
				23 01 00 00 00 00 02 D8 BF
				23 01 00 00 00 00 02 D9 02
				23 01 00 00 00 00 02 DA ED
				23 01 00 00 00 00 02 DB 03
				23 01 00 00 00 00 02 DC 0B
				23 01 00 00 00 00 02 DD 03
				23 01 00 00 00 00 02 DE 36
				23 01 00 00 00 00 02 DF 03
				23 01 00 00 00 00 02 E0 3B
				23 01 00 00 00 00 02 E1 03
				23 01 00 00 00 00 02 E2 40
				23 01 00 00 00 00 02 E3 03
				23 01 00 00 00 00 02 E4 45
				23 01 00 00 00 00 02 E5 03
				23 01 00 00 00 00 02 E6 54
				23 01 00 00 00 00 02 E7 03
				23 01 00 00 00 00 02 E8 70
				23 01 00 00 00 00 02 E9 03
				23 01 00 00 00 00 02 EA 8E
				23 01 00 00 00 00 02 EB 03
				23 01 00 00 00 00 02 EC B2
				23 01 00 00 00 00 02 ED 03
				23 01 00 00 00 00 02 EE C9
				23 01 00 00 00 00 02 EF 00
				23 01 00 00 00 00 02 F0 30
				23 01 00 00 00 00 02 F1 00
				23 01 00 00 00 00 02 F2 43
				23 01 00 00 00 00 02 F3 00
				23 01 00 00 00 00 02 F4 61
				23 01 00 00 00 00 02 F5 00
				23 01 00 00 00 00 02 F6 7D
				23 01 00 00 00 00 02 F7 00
				23 01 00 00 00 00 02 F8 98
				23 01 00 00 00 00 02 F9 00
				23 01 00 00 00 00 02 FA AE
				23 01 00 00 00 00 02 FB 01
				23 01 00 00 00 00 02 FF 02
				23 01 00 00 00 00 02 00 00
				23 01 00 00 00 00 02 01 C0
				23 01 00 00 00 00 02 02 00
				23 01 00 00 00 00 02 03 CD
				23 01 00 00 00 00 02 04 00
				23 01 00 00 00 00 02 05 DB
				23 01 00 00 00 00 02 06 01
				23 01 00 00 00 00 02 07 0A
				23 01 00 00 00 00 02 08 01
				23 01 00 00 00 00 02 09 2A
				23 01 00 00 00 00 02 0A 01
				23 01 00 00 00 00 02 0B 69
				23 01 00 00 00 00 02 0C 01
				23 01 00 00 00 00 02 0D 99
				23 01 00 00 00 00 02 0E 01
				23 01 00 00 00 00 02 0F DE
				23 01 00 00 00 00 02 10 02
				23 01 00 00 00 00 02 11 20
				23 01 00 00 00 00 02 12 02
				23 01 00 00 00 00 02 13 22
				23 01 00 00 00 00 02 14 02
				23 01 00 00 00 00 02 15 64
				23 01 00 00 00 00 02 16 02
				23 01 00 00 00 00 02 17 A0
				23 01 00 00 00 00 02 18 02
				23 01 00 00 00 00 02 19 C4
				23 01 00 00 00 00 02 1A 02
				23 01 00 00 00 00 02 1B F3
				23 01 00 00 00 00 02 1C 03
				23 01 00 00 00 00 02 1D 0F
				23 01 00 00 00 00 02 1E 03
				23 01 00 00 00 00 02 1F 36
				23 01 00 00 00 00 02 20 03
				23 01 00 00 00 00 02 21 3B
				23 01 00 00 00 00 02 22 03
				23 01 00 00 00 00 02 23 40
				23 01 00 00 00 00 02 24 03
				23 01 00 00 00 00 02 25 45
				23 01 00 00 00 00 02 26 03
				23 01 00 00 00 00 02 27 54
				23 01 00 00 00 00 02 28 03
				23 01 00 00 00 00 02 29 70
				23 01 00 00 00 00 02 2A 03
				23 01 00 00 00 00 02 2B 8E
				23 01 00 00 00 00 02 2D 03
				23 01 00 00 00 00 02 2F B2
				23 01 00 00 00 00 02 30 03
				23 01 00 00 00 00 02 31 C9
				23 01 00 00 00 00 02 32 00
				23 01 00 00 00 00 02 33 30
				23 01 00 00 00 00 02 34 00
				23 01 00 00 00 00 02 35 43
				23 01 00 00 00 00 02 36 00
				23 01 00 00 00 00 02 37 61
				23 01 00 00 00 00 02 38 00
				23 01 00 00 00 00 02 39 7D
				23 01 00 00 00 00 02 3A 00
				23 01 00 00 00 00 02 3B 98
				23 01 00 00 00 00 02 3D 00
				23 01 00 00 00 00 02 3F AE
				23 01 00 00 00 00 02 40 00
				23 01 00 00 00 00 02 41 C0
				23 01 00 00 00 00 02 42 00
				23 01 00 00 00 00 02 43 CD
				23 01 00 00 00 00 02 44 00
				23 01 00 00 00 00 02 45 DB
				23 01 00 00 00 00 02 46 01
				23 01 00 00 00 00 02 47 0A
				23 01 00 00 00 00 02 48 01
				23 01 00 00 00 00 02 49 2A
				23 01 00 00 00 00 02 4A 01
				23 01 00 00 00 00 02 4B 69
				23 01 00 00 00 00 02 4C 01
				23 01 00 00 00 00 02 4D 99
				23 01 00 00 00 00 02 4E 01
				23 01 00 00 00 00 02 4F DE
				23 01 00 00 00 00 02 50 02
				23 01 00 00 00 00 02 51 20
				23 01 00 00 00 00 02 52 02
				23 01 00 00 00 00 02 53 22
				23 01 00 00 00 00 02 54 02
				23 01 00 00 00 00 02 55 64
				23 01 00 00 00 00 02 56 02
				23 01 00 00 00 00 02 58 A0
				23 01 00 00 00 00 02 59 02
				23 01 00 00 00 00 02 5A C4
				23 01 00 00 00 00 02 5B 02
				23 01 00 00 00 00 02 5C F3
				23 01 00 00 00 00 02 5D 03
				23 01 00 00 00 00 02 5E 0F
				23 01 00 00 00 00 02 5F 03
				23 01 00 00 00 00 02 60 36
				23 01 00 00 00 00 02 61 03
				23 01 00 00 00 00 02 62 3B
				23 01 00 00 00 00 02 63 03
				23 01 00 00 00 00 02 64 40
				23 01 00 00 00 00 02 65 03
				23 01 00 00 00 00 02 66 45
				23 01 00 00 00 00 02 67 03
				23 01 00 00 00 00 02 68 54
				23 01 00 00 00 00 02 69 03
				23 01 00 00 00 00 02 6A 70
				23 01 00 00 00 00 02 6B 03
				23 01 00 00 00 00 02 6C 8E
				23 01 00 00 00 00 02 6D 03
				23 01 00 00 00 00 02 6E B2
				23 01 00 00 00 00 02 6F 03
				23 01 00 00 00 00 02 70 C9
				23 01 00 00 00 00 02 71 00
				23 01 00 00 00 00 02 72 30
				23 01 00 00 00 00 02 73 00
				23 01 00 00 00 00 02 74 43
				23 01 00 00 00 00 02 75 00
				23 01 00 00 00 00 02 76 61
				23 01 00 00 00 00 02 77 00
				23 01 00 00 00 00 02 78 7D
				23 01 00 00 00 00 02 79 00
				23 01 00 00 00 00 02 7A 98
				23 01 00 00 00 00 02 7B 00
				23 01 00 00 00 00 02 7C AE
				23 01 00 00 00 00 02 7D 00
				23 01 00 00 00 00 02 7E C0
				23 01 00 00 00 00 02 7F 00
				23 01 00 00 00 00 02 80 CD
				23 01 00 00 00 00 02 81 00
				23 01 00 00 00 00 02 82 DB
				23 01 00 00 00 00 02 83 01
				23 01 00 00 00 00 02 84 0A
				23 01 00 00 00 00 02 85 01
				23 01 00 00 00 00 02 86 2A
				23 01 00 00 00 00 02 87 01
				23 01 00 00 00 00 02 88 63
				23 01 00 00 00 00 02 89 01
				23 01 00 00 00 00 02 8A 90
				23 01 00 00 00 00 02 8B 01
				23 01 00 00 00 00 02 8C D2
				23 01 00 00 00 00 02 8D 02
				23 01 00 00 00 00 02 8E 14
				23 01 00 00 00 00 02 8F 02
				23 01 00 00 00 00 02 90 16
				23 01 00 00 00 00 02 91 02
				23 01 00 00 00 00 02 92 58
				23 01 00 00 00 00 02 93 02
				23 01 00 00 00 00 02 94 95
				23 01 00 00 00 00 02 95 02
				23 01 00 00 00 00 02 96 BC
				23 01 00 00 00 00 02 97 02
				23 01 00 00 00 00 02 98 ED
				23 01 00 00 00 00 02 99 03
				23 01 00 00 00 00 02 9A 0B
				23 01 00 00 00 00 02 9B 03
				23 01 00 00 00 00 02 9C 36
				23 01 00 00 00 00 02 9D 03
				23 01 00 00 00 00 02 9E 3B
				23 01 00 00 00 00 02 9F 03
				23 01 00 00 00 00 02 A0 40
				23 01 00 00 00 00 02 A2 03
				23 01 00 00 00 00 02 A3 45
				23 01 00 00 00 00 02 A4 03
				23 01 00 00 00 00 02 A5 54
				23 01 00 00 00 00 02 A6 03
				23 01 00 00 00 00 02 A7 70
				23 01 00 00 00 00 02 A9 03
				23 01 00 00 00 00 02 AA 8E
				23 01 00 00 00 00 02 AB 03
				23 01 00 00 00 00 02 AC B2
				23 01 00 00 00 00 02 AD 03
				23 01 00 00 00 00 02 AE C9
				23 01 00 00 00 00 02 AF 00
				23 01 00 00 00 00 02 B0 30
				23 01 00 00 00 00 02 B1 00
				23 01 00 00 00 00 02 B2 43
				23 01 00 00 00 00 02 B3 00
				23 01 00 00 00 00 02 B4 61
				23 01 00 00 00 00 02 B5 00
				23 01 00 00 00 00 02 B6 7D
				23 01 00 00 00 00 02 B7 00
				23 01 00 00 00 00 02 B8 98
				23 01 00 00 00 00 02 B9 00
				23 01 00 00 00 00 02 BA AE
				23 01 00 00 00 00 02 BB 00
				23 01 00 00 00 00 02 BC C0
				23 01 00 00 00 00 02 BD 00
				23 01 00 00 00 00 02 BE CD
				23 01 00 00 00 00 02 BF 00
				23 01 00 00 00 00 02 C0 DB
				23 01 00 00 00 00 02 C1 01
				23 01 00 00 00 00 02 C2 0A
				23 01 00 00 00 00 02 C3 01
				23 01 00 00 00 00 02 C4 2A
				23 01 00 00 00 00 02 C5 01
				23 01 00 00 00 00 02 C6 63
				23 01 00 00 00 00 02 C7 01
				23 01 00 00 00 00 02 C8 90
				23 01 00 00 00 00 02 C9 01
				23 01 00 00 00 00 02 CA D2
				23 01 00 00 00 00 02 CB 02
				23 01 00 00 00 00 02 CC 14
				23 01 00 00 00 00 02 CD 02
				23 01 00 00 00 00 02 CE 16
				23 01 00 00 00 00 02 CF 02
				23 01 00 00 00 00 02 D0 58
				23 01 00 00 00 00 02 D1 02
				23 01 00 00 00 00 02 D2 95
				23 01 00 00 00 00 02 D3 02
				23 01 00 00 00 00 02 D4 BC
				23 01 00 00 00 00 02 D5 02
				23 01 00 00 00 00 02 D6 ED
				23 01 00 00 00 00 02 D7 03
				23 01 00 00 00 00 02 D8 0B
				23 01 00 00 00 00 02 D9 03
				23 01 00 00 00 00 02 DA 36
				23 01 00 00 00 00 02 DB 03
				23 01 00 00 00 00 02 DC 3B
				23 01 00 00 00 00 02 DD 03
				23 01 00 00 00 00 02 DE 40
				23 01 00 00 00 00 02 DF 03
				23 01 00 00 00 00 02 E0 45
				23 01 00 00 00 00 02 E1 03
				23 01 00 00 00 00 02 E2 54
				23 01 00 00 00 00 02 E3 03
				23 01 00 00 00 00 02 E4 70
				23 01 00 00 00 00 02 E5 03
				23 01 00 00 00 00 02 E6 8E
				23 01 00 00 00 00 02 E7 03
				23 01 00 00 00 00 02 E8 B2
				23 01 00 00 00 00 02 E9 03
				23 01 00 00 00 00 02 EA C9
				23 01 00 00 00 00 02 FB 01
				23 01 00 00 00 00 02 FF 01
				23 01 00 00 00 00 02 0B 4B
				23 01 00 00 00 00 02 0C 4B
				23 01 00 00 00 00 02 0E A1
				23 01 00 00 00 00 02 15 0B
				23 01 00 00 00 00 02 16 0B
				23 01 00 00 00 00 02 1B 1B
				23 01 00 00 00 00 02 1C F5
				23 01 00 00 00 00 02 01 44
				23 01 00 00 00 00 02 5C 82
				23 01 00 00 00 00 02 5E 02
				23 01 00 00 00 00 02 60 0F
				23 01 00 00 00 00 02 66 01
				23 01 00 00 00 00 02 69 99
				23 01 00 00 00 00 02 6D 33
				23 01 00 00 00 00 02 FB 01
				23 01 00 00 00 00 02 FF 05
				23 01 00 00 00 00 02 35 6B
				23 01 00 00 00 00 02 7E 02
				23 01 00 00 00 00 02 7F 18
				23 01 00 00 00 00 02 81 05
				23 01 00 00 00 00 02 82 05
				23 01 00 00 00 00 02 A6 04
				23 01 00 00 00 00 02 84 03
				23 01 00 00 00 00 02 85 04
				15 01 00 00 00 00 02 C6 00
				23 01 00 00 00 00 02 FB 01
				23 01 00 00 00 00 02 FF FF
				23 01 00 00 00 00 02 4F 03
				23 01 00 00 00 00 02 FB 01
				23 01 00 00 00 00 02 FF 00
				15 01 00 00 00 00 02 D3 08
				15 01 00 00 00 00 02 D4 1B
				15 01 00 00 00 00 02 D5 50
				15 01 00 00 00 00 02 D6 70];
		qcom,mdss-dsi-on-command = [05 01 00 00 78 00 01 11
				05 01 00 00 00 00 01 29];
		qcom,mdss-dsi-off-command = [05 01 00 00 14 00 01 28
				05 01 00 00 50 00 01 10];
		qcom,mdss-dsi-on-command-state = "dsi_lp_mode";
		qcom,mdss-dsi-off-command-state = "dsi_hs_mode";
		qcom,mdss-dsi-h-sync-pulse = <1>;
		qcom,mdss-dsi-traffic-mode = "non_burst_sync_event";
		qcom,mdss-dsi-bllp-eof-power-mode;
		qcom,mdss-dsi-bllp-power-mode;
		qcom,mdss-dsi-lane-0-state;
		qcom,mdss-dsi-lane-1-state;
		qcom,mdss-dsi-lane-2-state;
		qcom,mdss-dsi-lane-3-state;
		qcom,mdss-dsi-panel-timings = [E6 38 26 00 68 6C 2A 3C 2C 03 04 00];
		qcom,mdss-dsi-lp11-init;
		qcom,mdss-dsi-t-clk-post = <0x02>;
		qcom,mdss-dsi-t-clk-pre = <0x2B>;
		qcom,mdss-dsi-bl-min-level = <1>;
		qcom,mdss-dsi-bl-max-level = <4095>;
		qcom,mdss-brightness-max-level = <4095>;
		qcom,mdss-dsi-dma-trigger = "trigger_sw";
		qcom,mdss-dsi-mdp-trigger = "none";
		qcom,mdss-dsi-bl-pmic-control-type = "bl_ctrl_wled";
		qcom,mdss-dsi-pan-enable-dynamic-fps;
		qcom,mdss-dsi-pan-fps-update = "dfps_suspend_resume_mode";
		qcom,cont-splash-enabled;

		somc,driver-ic = <1>;
		somc,dric-gpio = <&msmgpio 26 0>;
		somc,mul-channel-scaling = <3>;
		somc,mdss-phy-size-mm = <64 114>;
		somc,mdss-dsi-lane-config = [00 c2 ef 00 00 00 00 01 75
				00 c2 ef 00 00 00 00 01 75
				00 c2 ef 00 00 00 00 01 75
				00 c2 ef 00 00 00 00 01 75
				00 02 45 00 00 00 00 01 97];
		somc,mdss-dsi-disp-on-in-hs = <1>;
		somc,lcd-id = <1>;
		somc,lcd-id-adc = <1087000 1231000>;
		somc,disp-en-on-pre = <5>;
		somc,disp-en-on-post = <20>;
		somc,disp-en-off-post = <70>;
		somc,pw-on-rst-seq = <1 10>;
		somc,pw-off-rst-seq = <0 0>;
		somc,pw-down-period = <200>;

		somc,mdss-dsi-pre-uv-command = [15 01 00 00 00 00 02 FF 00];
		somc,mdss-dsi-uv-command = [06 01 00 00 00 00 01 DA
					06 01 00 00 00 00 01 DB];
		somc,mdss-dsi-uv-param-type = <2>;
		somc,mdss-dsi-pcc-table-size = <73>;
		somc,mdss-dsi-pcc-table = <
			0x00 0x01 0x10 0x13 0x28 0x2B 0x8000 0x7400 0x8000
			0x00 0x02 0x14 0x17 0x28 0x2B 0x7a80 0x7400 0x7e00
			0x00 0x03 0x18 0x1B 0x28 0x2B 0x7480 0x7380 0x8000
			0x00 0x04 0x1C 0x1F 0x28 0x2B 0x7280 0x7380 0x8000
			0x00 0x05 0x20 0x23 0x28 0x2B 0x6e00 0x7400 0x8000
			0x00 0x06 0x0C 0x0F 0x24 0x27 0x7f80 0x7200 0x7c00
			0x00 0x07 0x10 0x13 0x24 0x27 0x8000 0x7400 0x7d80
			0x00 0x08 0x14 0x17 0x24 0x27 0x7d00 0x7700 0x7e00
			0x00 0x09 0x18 0x1B 0x24 0x27 0x7700 0x7600 0x8000
			0x00 0x0A 0x1C 0x1F 0x24 0x27 0x7380 0x7500 0x7c00
			0x00 0x0B 0x20 0x23 0x24 0x27 0x6f00 0x7500 0x7e80
			0x00 0x0C 0x0C 0x0F 0x20 0x23 0x7f80 0x7200 0x7900
			0x00 0x0D 0x10 0x13 0x20 0x23 0x8000 0x7400 0x7b00
			0x00 0x0E 0x14 0x17 0x20 0x23 0x7a80 0x7400 0x7b00
			0x00 0x0F 0x18 0x1B 0x20 0x23 0x7800 0x7700 0x7e80
			0x00 0x10 0x1C 0x1F 0x20 0x23 0x7780 0x7900 0x7f80
			0x00 0x11 0x20 0x23 0x20 0x23 0x7300 0x7900 0x7f00
			0x00 0x12 0x24 0x27 0x20 0x23 0x7100 0x7980 0x8000
			0x00 0x13 0x0C 0x0F 0x1C 0x1F 0x7f80 0x7200 0x7700
			0x00 0x14 0x10 0x13 0x1C 0x1F 0x7c00 0x7000 0x7580
			0x00 0x15 0x14 0x17 0x1C 0x1F 0x7f80 0x7900 0x7e00
			0x00 0x16 0x18 0x1B 0x1C 0x1F 0x7c00 0x7a00 0x7d80
			0x00 0x17 0x1C 0x1F 0x1C 0x1F 0x7900 0x7a00 0x7e00
			0x00 0x18 0x20 0x23 0x1C 0x1F 0x7600 0x7c80 0x8000
			0x00 0x19 0x24 0x27 0x1C 0x1F 0x7300 0x7c00 0x7e80
			0x00 0x1A 0x0C 0x0F 0x18 0x1B 0x8000 0x7200 0x7300
			0x00 0x1B 0x10 0x13 0x18 0x1B 0x7e80 0x7200 0x7500
			0x00 0x1C 0x14 0x17 0x18 0x1B 0x7f00 0x7900 0x7b80
			0x00 0x1D 0x18 0x1B 0x18 0x1B 0x7f00 0x7d00 0x7e00
			0x00 0x1E 0x1C 0x1F 0x18 0x1B 0x7d00 0x7d80 0x8000
			0x00 0x1F 0x20 0x23 0x18 0x1B 0x7900 0x7f00 0x8000
			0x00 0x20 0x24 0x27 0x18 0x1B 0x7780 0x8000 0x8000
			0x00 0x21 0x10 0x13 0x14 0x17 0x7f80 0x7380 0x7200
			0x00 0x22 0x14 0x17 0x14 0x17 0x7f00 0x7900 0x7900
			0x00 0x23 0x18 0x1B 0x14 0x17 0x7f00 0x7d00 0x7b80
			0xFF 0x00 0x1C 0x1F 0x14 0x17 0x8000 0x8000 0x8000
			0x00 0x24 0x20 0x23 0x14 0x17 0x7a00 0x8000 0x7e80
			0x00 0x25 0x24 0x27 0x14 0x17 0x7780 0x8000 0x7d80
			0x00 0x26 0x10 0x13 0x10 0x13 0x8000 0x7400 0x7000
			0x00 0x27 0x14 0x17 0x10 0x13 0x7f80 0x7900 0x7680
			0x00 0x28 0x18 0x1B 0x10 0x13 0x8000 0x7d80 0x7980
			0x00 0x29 0x1C 0x1F 0x10 0x13 0x8000 0x8000 0x7c00
			0x00 0x2A 0x20 0x23 0x10 0x13 0x7a00 0x8000 0x7c00
			0x00 0x2B 0x10 0x13 0x0C 0x0F 0x7f80 0x7480 0x6f00
			0x00 0x2C 0x14 0x17 0x0C 0x0F 0x7f80 0x7900 0x7400
			0x00 0x2D 0x18 0x1B 0x0C 0x0F 0x7f80 0x7d80 0x7680
			0x00 0x2E 0x1C 0x1F 0x0C 0x0F 0x8000 0x8000 0x7980
			0x01 0x00 0x00 0x09 0x32 0x3B 0x8000 0x6D00 0x8000
			0x02 0x00 0x0A 0x13 0x32 0x3B 0x7A00 0x7100 0x8000
			0x03 0x00 0x14 0x1D 0x32 0x3B 0x7400 0x7180 0x8000
			0x04 0x00 0x1E 0x27 0x32 0x3B 0x7100 0x7200 0x8000
			0x05 0x00 0x28 0x31 0x32 0x3B 0x6C80 0x7180 0x8000
			0x06 0x00 0x32 0x3B 0x32 0x3B 0x6680 0x7300 0x8000
			0x07 0x00 0x00 0x09 0x28 0x31 0x8000 0x6B80 0x7080
			0x08 0x00 0x0A 0x13 0x28 0x31 0x8000 0x7400 0x8000
			0x09 0x00 0x14 0x1D 0x28 0x31 0x7A00 0x7700 0x8000
			0x0A 0x00 0x1E 0x27 0x28 0x31 0x7600 0x7780 0x8000
			0x0B 0x00 0x28 0x31 0x28 0x31 0x6F80 0x7980 0x8000
			0x0C 0x00 0x32 0x3B 0x28 0x31 0x7080 0x7E80 0x8000
			0x0D 0x00 0x00 0x09 0x14 0x27 0x8000 0x6B00 0x6D00
			0x0E 0x00 0x0A 0x13 0x14 0x27 0x8000 0x7380 0x7480
			0xFF 0x00 0x14 0x27 0x14 0x27 0x8000 0x8000 0x8000
			0x10 0x00 0x28 0x31 0x14 0x27 0x7500 0x8000 0x7E80
			0x11 0x00 0x32 0x3B 0x14 0x27 0x7100 0x8000 0x7C80
			0x12 0x00 0x00 0x09 0x00 0x09 0x8000 0x6900 0x6500
			0x13 0x00 0x00 0x13 0x0A 0x13 0x8000 0x7300 0x6F00
			0x13 0x00 0x0A 0x13 0x00 0x09 0x8000 0x7300 0x6F00
			0x14 0x00 0x14 0x27 0x0A 0x13 0x7F00 0x8000 0x7900
			0x15 0x00 0x14 0x27 0x00 0x09 0x7E80 0x8000 0x7680
			0x16 0x00 0x28 0x31 0x0A 0x13 0x7380 0x8000 0x7600
			0x17 0x00 0x32 0x3B 0x0A 0x13 0x7080 0x8000 0x7900
			0x18 0x00 0x28 0x31 0x00 0x09 0x7A00 0x8000 0x7580
			0x19 0x00 0x32 0x3B 0x00 0x09 0x6F00 0x8000 0x7200>;
	};

	dsi_novatek_sharp_1080_vid: somc,novatek_sharp_1080p_panel {
		qcom,mdss-dsi-panel-name = "sharp novatek 1080p video";
		qcom,mdss-dsi-panel-controller = <&mdss_dsi0>;
		qcom,mdss-dsi-panel-type = "dsi_video_mode";
		qcom,mdss-dsi-panel-destination = "display_1";
		qcom,mdss-dsi-panel-framerate = <60>;
		qcom,mdss-dsi-virtual-channel-id = <0>;
		qcom,mdss-dsi-stream = <0>;
		qcom,mdss-dsi-panel-width = <1080>;
		qcom,mdss-dsi-panel-height = <1920>;
		qcom,mdss-dsi-h-front-porch = <128>;
		qcom,mdss-dsi-h-back-porch = <76>;
		qcom,mdss-dsi-h-pulse-width = <4>;
		qcom,mdss-dsi-h-sync-skew = <0>;
		qcom,mdss-dsi-v-back-porch = <3>;
		qcom,mdss-dsi-v-front-porch = <4>;
		qcom,mdss-dsi-v-pulse-width = <2>;
		qcom,mdss-dsi-h-left-border = <0>;
		qcom,mdss-dsi-h-right-border = <0>;
		qcom,mdss-dsi-v-top-border = <0>;
		qcom,mdss-dsi-v-bottom-border = <0>;
		qcom,mdss-dsi-bpp = <24>;
		qcom,mdss-dsi-underflow-color = <0x0>;
		qcom,mdss-dsi-border-color = <0>;
		somc,mdss-dsi-init-command = [15 01 00 00 00 00 02 FF 01
				15 01 00 00 00 00 02 FB 01
				15 01 00 00 00 00 02 15 14
				15 01 00 00 00 00 02 16 12
				15 01 00 00 00 00 02 58 82
				15 01 00 00 00 00 02 59 00
				15 01 00 00 00 00 02 5A 02
				15 01 00 00 00 00 02 5B 00
				15 01 00 00 00 00 02 5C 82
				15 01 00 00 00 00 02 5D 00
				15 01 00 00 00 00 02 5E 02
				15 01 00 00 00 00 02 5F 00
				15 01 00 00 00 00 02 60 0F
				15 01 00 00 00 00 02 6D 22
				15 01 00 00 00 00 02 FF 05
				15 01 00 00 00 00 02 FB 01
				15 01 00 00 00 00 02 A6 04
				15 01 00 00 00 00 02 C4 04
				15 01 00 00 00 00 02 FF 00
				15 01 00 00 00 00 02 FF 01
				15 01 00 00 00 00 02 FB 01
				15 01 00 00 00 00 02 75 00
				15 01 00 00 00 00 02 76 21
				15 01 00 00 00 00 02 77 00
				15 01 00 00 00 00 02 78 57
				15 01 00 00 00 00 02 79 00
				15 01 00 00 00 00 02 7A 8A
				15 01 00 00 00 00 02 7B 00
				15 01 00 00 00 00 02 7C A9
				15 01 00 00 00 00 02 7D 00
				15 01 00 00 00 00 02 7E C1
				15 01 00 00 00 00 02 7F 00
				15 01 00 00 00 00 02 80 D6
				15 01 00 00 00 00 02 81 00
				15 01 00 00 00 00 02 82 E4
				15 01 00 00 00 00 02 83 00
				15 01 00 00 00 00 02 84 F6
				15 01 00 00 00 00 02 85 01
				15 01 00 00 00 00 02 86 06
				15 01 00 00 00 00 02 87 01
				15 01 00 00 00 00 02 88 33
				15 01 00 00 00 00 02 89 01
				15 01 00 00 00 00 02 8A 59
				15 01 00 00 00 00 02 8B 01
				15 01 00 00 00 00 02 8C 95
				15 01 00 00 00 00 02 8D 01
				15 01 00 00 00 00 02 8E C5
				15 01 00 00 00 00 02 8F 02
				15 01 00 00 00 00 02 90 11
				15 01 00 00 00 00 02 91 02
				15 01 00 00 00 00 02 92 4D
				15 01 00 00 00 00 02 93 02
				15 01 00 00 00 00 02 94 4F
				15 01 00 00 00 00 02 95 02
				15 01 00 00 00 00 02 96 77
				15 01 00 00 00 00 02 97 02
				15 01 00 00 00 00 02 98 A2
				15 01 00 00 00 00 02 99 02
				15 01 00 00 00 00 02 9A BE
				15 01 00 00 00 00 02 9B 02
				15 01 00 00 00 00 02 9C E5
				15 01 00 00 00 00 02 9D 03
				15 01 00 00 00 00 02 9E 04
				15 01 00 00 00 00 02 9F 03
				15 01 00 00 00 00 02 A0 2C
				15 01 00 00 00 00 02 A2 03
				15 01 00 00 00 00 02 A3 39
				15 01 00 00 00 00 02 A4 03
				15 01 00 00 00 00 02 A5 46
				15 01 00 00 00 00 02 A6 03
				15 01 00 00 00 00 02 A7 55
				15 01 00 00 00 00 02 A9 03
				15 01 00 00 00 00 02 AA 66
				15 01 00 00 00 00 02 AB 03
				15 01 00 00 00 00 02 AC 7B
				15 01 00 00 00 00 02 AD 03
				15 01 00 00 00 00 02 AE 95
				15 01 00 00 00 00 02 AF 03
				15 01 00 00 00 00 02 B0 B4
				15 01 00 00 00 00 02 B1 03
				15 01 00 00 00 00 02 B2 BB
				15 01 00 00 00 00 02 B3 00
				15 01 00 00 00 00 02 B4 5B
				15 01 00 00 00 00 02 B5 00
				15 01 00 00 00 00 02 B6 94
				15 01 00 00 00 00 02 B7 00
				15 01 00 00 00 00 02 B8 C2
				15 01 00 00 00 00 02 B9 00
				15 01 00 00 00 00 02 BA DE
				15 01 00 00 00 00 02 BB 00
				15 01 00 00 00 00 02 BC F5
				15 01 00 00 00 00 02 BD 01
				15 01 00 00 00 00 02 BE 09
				15 01 00 00 00 00 02 BF 01
				15 01 00 00 00 00 02 C0 15
				15 01 00 00 00 00 02 C1 01
				15 01 00 00 00 00 02 C2 26
				15 01 00 00 00 00 02 C3 01
				15 01 00 00 00 00 02 C4 34
				15 01 00 00 00 00 02 C5 01
				15 01 00 00 00 00 02 C6 5C
				15 01 00 00 00 00 02 C7 01
				15 01 00 00 00 00 02 C8 7C
				15 01 00 00 00 00 02 C9 01
				15 01 00 00 00 00 02 CA AC
				15 01 00 00 00 00 02 CB 01
				15 01 00 00 00 00 02 CC D2
				15 01 00 00 00 00 02 CD 02
				15 01 00 00 00 00 02 CE 0D
				15 01 00 00 00 00 02 CF 02
				15 01 00 00 00 00 02 D0 3B
				15 01 00 00 00 00 02 D1 02
				15 01 00 00 00 00 02 D2 3D
				15 01 00 00 00 00 02 D3 02
				15 01 00 00 00 00 02 D4 73
				15 01 00 00 00 00 02 D5 02
				15 01 00 00 00 00 02 D6 AD
				15 01 00 00 00 00 02 D7 02
				15 01 00 00 00 00 02 D8 CF
				15 01 00 00 00 00 02 D9 02
				15 01 00 00 00 00 02 DA FE
				15 01 00 00 00 00 02 DB 03
				15 01 00 00 00 00 02 DC 1C
				15 01 00 00 00 00 02 DD 03
				15 01 00 00 00 00 02 DE 44
				15 01 00 00 00 00 02 DF 03
				15 01 00 00 00 00 02 E0 51
				15 01 00 00 00 00 02 E1 03
				15 01 00 00 00 00 02 E2 5E
				15 01 00 00 00 00 02 E3 03
				15 01 00 00 00 00 02 E4 6E
				15 01 00 00 00 00 02 E5 03
				15 01 00 00 00 00 02 E6 7F
				15 01 00 00 00 00 02 E7 03
				15 01 00 00 00 00 02 E8 93
				15 01 00 00 00 00 02 E9 03
				15 01 00 00 00 00 02 EA AC
				15 01 00 00 00 00 02 EB 03
				15 01 00 00 00 00 02 EC CA
				15 01 00 00 00 00 02 ED 03
				15 01 00 00 00 00 02 EE D1
				15 01 00 00 00 00 02 EF 00
				15 01 00 00 00 00 02 F0 14
				15 01 00 00 00 00 02 F1 00
				15 01 00 00 00 00 02 F2 50
				15 01 00 00 00 00 02 F3 00
				15 01 00 00 00 00 02 F4 84
				15 01 00 00 00 00 02 F5 00
				15 01 00 00 00 00 02 F6 A4
				15 01 00 00 00 00 02 F7 00
				15 01 00 00 00 00 02 F8 B9
				15 01 00 00 00 00 02 F9 00
				15 01 00 00 00 00 02 FA D2
				15 01 00 00 00 00 02 FF 02
				15 01 00 00 00 00 02 FB 01
				15 01 00 00 00 00 02 00 00
				15 01 00 00 00 00 02 01 E1
				15 01 00 00 00 00 02 02 00
				15 01 00 00 00 00 02 03 F1
				15 01 00 00 00 00 02 04 01
				15 01 00 00 00 00 02 05 02
				15 01 00 00 00 00 02 06 01
				15 01 00 00 00 00 02 07 31
				15 01 00 00 00 00 02 08 01
				15 01 00 00 00 00 02 09 56
				15 01 00 00 00 00 02 0A 01
				15 01 00 00 00 00 02 0B 93
				15 01 00 00 00 00 02 0C 01
				15 01 00 00 00 00 02 0D C4
				15 01 00 00 00 00 02 0E 02
				15 01 00 00 00 00 02 0F 0F
				15 01 00 00 00 00 02 10 02
				15 01 00 00 00 00 02 11 4B
				15 01 00 00 00 00 02 12 02
				15 01 00 00 00 00 02 13 4C
				15 01 00 00 00 00 02 14 02
				15 01 00 00 00 00 02 15 75
				15 01 00 00 00 00 02 16 02
				15 01 00 00 00 00 02 17 A0
				15 01 00 00 00 00 02 18 02
				15 01 00 00 00 00 02 19 BB
				15 01 00 00 00 00 02 1A 02
				15 01 00 00 00 00 02 1B E0
				15 01 00 00 00 00 02 1C 02
				15 01 00 00 00 00 02 1D FF
				15 01 00 00 00 00 02 1E 03
				15 01 00 00 00 00 02 1F 27
				15 01 00 00 00 00 02 20 03
				15 01 00 00 00 00 02 21 33
				15 01 00 00 00 00 02 22 03
				15 01 00 00 00 00 02 23 41
				15 01 00 00 00 00 02 24 03
				15 01 00 00 00 00 02 25 50
				15 01 00 00 00 00 02 26 03
				15 01 00 00 00 00 02 27 61
				15 01 00 00 00 00 02 28 03
				15 01 00 00 00 00 02 29 76
				15 01 00 00 00 00 02 2A 03
				15 01 00 00 00 00 02 2B 91
				15 01 00 00 00 00 02 2D 03
				15 01 00 00 00 00 02 2F B3
				15 01 00 00 00 00 02 30 03
				15 01 00 00 00 00 02 31 BB
				15 01 00 00 00 00 02 32 00
				15 01 00 00 00 00 02 33 4E
				15 01 00 00 00 00 02 34 00
				15 01 00 00 00 00 02 35 8F
				15 01 00 00 00 00 02 36 00
				15 01 00 00 00 00 02 37 BE
				15 01 00 00 00 00 02 38 00
				15 01 00 00 00 00 02 39 DB
				15 01 00 00 00 00 02 3A 00
				15 01 00 00 00 00 02 3B EF
				15 01 00 00 00 00 02 3D 01
				15 01 00 00 00 00 02 3F 06
				15 01 00 00 00 00 02 40 01
				15 01 00 00 00 00 02 41 13
				15 01 00 00 00 00 02 42 01
				15 01 00 00 00 00 02 43 22
				15 01 00 00 00 00 02 44 01
				15 01 00 00 00 00 02 45 31
				15 01 00 00 00 00 02 46 01
				15 01 00 00 00 00 02 47 5B
				15 01 00 00 00 00 02 48 01
				15 01 00 00 00 00 02 49 7B
				15 01 00 00 00 00 02 4A 01
				15 01 00 00 00 00 02 4B AB
				15 01 00 00 00 00 02 4C 01
				15 01 00 00 00 00 02 4D D1
				15 01 00 00 00 00 02 4E 02
				15 01 00 00 00 00 02 4F 0B
				15 01 00 00 00 00 02 50 02
				15 01 00 00 00 00 02 51 39
				15 01 00 00 00 00 02 52 02
				15 01 00 00 00 00 02 53 3A
				15 01 00 00 00 00 02 54 02
				15 01 00 00 00 00 02 55 71
				15 01 00 00 00 00 02 56 02
				15 01 00 00 00 00 02 58 AA
				15 01 00 00 00 00 02 59 02
				15 01 00 00 00 00 02 5A CC
				15 01 00 00 00 00 02 5B 02
				15 01 00 00 00 00 02 5C FA
				15 01 00 00 00 00 02 5D 03
				15 01 00 00 00 00 02 5E 17
				15 01 00 00 00 00 02 5F 03
				15 01 00 00 00 00 02 60 3F
				15 01 00 00 00 00 02 61 03
				15 01 00 00 00 00 02 62 4B
				15 01 00 00 00 00 02 63 03
				15 01 00 00 00 00 02 64 59
				15 01 00 00 00 00 02 65 03
				15 01 00 00 00 00 02 66 68
				15 01 00 00 00 00 02 67 03
				15 01 00 00 00 00 02 68 7A
				15 01 00 00 00 00 02 69 03
				15 01 00 00 00 00 02 6A 8E
				15 01 00 00 00 00 02 6B 03
				15 01 00 00 00 00 02 6C A8
				15 01 00 00 00 00 02 6D 03
				15 01 00 00 00 00 02 6E C9
				15 01 00 00 00 00 02 6F 03
				15 01 00 00 00 00 02 70 D1
				15 01 00 00 00 00 02 71 00
				15 01 00 00 00 00 02 72 00
				15 01 00 00 00 00 02 73 00
				15 01 00 00 00 00 02 74 38
				15 01 00 00 00 00 02 75 00
				15 01 00 00 00 00 02 76 6C
				15 01 00 00 00 00 02 77 00
				15 01 00 00 00 00 02 78 8F
				15 01 00 00 00 00 02 79 00
				15 01 00 00 00 00 02 7A AA
				15 01 00 00 00 00 02 7B 00
				15 01 00 00 00 00 02 7C BF
				15 01 00 00 00 00 02 7D 00
				15 01 00 00 00 00 02 7E D5
				15 01 00 00 00 00 02 7F 00
				15 01 00 00 00 00 02 80 E2
				15 01 00 00 00 00 02 81 00
				15 01 00 00 00 00 02 82 F3
				15 01 00 00 00 00 02 83 01
				15 01 00 00 00 00 02 84 27
				15 01 00 00 00 00 02 85 01
				15 01 00 00 00 00 02 86 4E
				15 01 00 00 00 00 02 87 01
				15 01 00 00 00 00 02 88 8D
				15 01 00 00 00 00 02 89 01
				15 01 00 00 00 00 02 8A C0
				15 01 00 00 00 00 02 8B 02
				15 01 00 00 00 00 02 8C 0D
				15 01 00 00 00 00 02 8D 02
				15 01 00 00 00 00 02 8E 4B
				15 01 00 00 00 00 02 8F 02
				15 01 00 00 00 00 02 90 4C
				15 01 00 00 00 00 02 91 02
				15 01 00 00 00 00 02 92 76
				15 01 00 00 00 00 02 93 02
				15 01 00 00 00 00 02 94 A1
				15 01 00 00 00 00 02 95 02
				15 01 00 00 00 00 02 96 BD
				15 01 00 00 00 00 02 97 02
				15 01 00 00 00 00 02 98 E4
				15 01 00 00 00 00 02 99 03
				15 01 00 00 00 00 02 9A 03
				15 01 00 00 00 00 02 9B 03
				15 01 00 00 00 00 02 9C 2D
				15 01 00 00 00 00 02 9D 03
				15 01 00 00 00 00 02 9E 39
				15 01 00 00 00 00 02 9F 03
				15 01 00 00 00 00 02 A0 46
				15 01 00 00 00 00 02 A2 03
				15 01 00 00 00 00 02 A3 56
				15 01 00 00 00 00 02 A4 03
				15 01 00 00 00 00 02 A5 68
				15 01 00 00 00 00 02 A6 03
				15 01 00 00 00 00 02 A7 7F
				15 01 00 00 00 00 02 A9 03
				15 01 00 00 00 00 02 AA 97
				15 01 00 00 00 00 02 AB 03
				15 01 00 00 00 00 02 AC B5
				15 01 00 00 00 00 02 AD 03
				15 01 00 00 00 00 02 AE BB
				15 01 00 00 00 00 02 AF 00
				15 01 00 00 00 00 02 B0 39
				15 01 00 00 00 00 02 B1 00
				15 01 00 00 00 00 02 B2 76
				15 01 00 00 00 00 02 B3 00
				15 01 00 00 00 00 02 B4 A6
				15 01 00 00 00 00 02 B5 00
				15 01 00 00 00 00 02 B6 C6
				15 01 00 00 00 00 02 B7 00
				15 01 00 00 00 00 02 B8 DF
				15 01 00 00 00 00 02 B9 00
				15 01 00 00 00 00 02 BA F2
				15 01 00 00 00 00 02 BB 01
				15 01 00 00 00 00 02 BC 07
				15 01 00 00 00 00 02 BD 01
				15 01 00 00 00 00 02 BE 13
				15 01 00 00 00 00 02 BF 01
				15 01 00 00 00 00 02 C0 22
				15 01 00 00 00 00 02 C1 01
				15 01 00 00 00 00 02 C2 50
				15 01 00 00 00 00 02 C3 01
				15 01 00 00 00 00 02 C4 72
				15 01 00 00 00 00 02 C5 01
				15 01 00 00 00 00 02 C6 A5
				15 01 00 00 00 00 02 C7 01
				15 01 00 00 00 00 02 C8 CD
				15 01 00 00 00 00 02 C9 02
				15 01 00 00 00 00 02 CA 09
				15 01 00 00 00 00 02 CB 02
				15 01 00 00 00 00 02 CC 39
				15 01 00 00 00 00 02 CD 02
				15 01 00 00 00 00 02 CE 3A
				15 01 00 00 00 00 02 CF 02
				15 01 00 00 00 00 02 D0 72
				15 01 00 00 00 00 02 D1 02
				15 01 00 00 00 00 02 D2 AC
				15 01 00 00 00 00 02 D3 02
				15 01 00 00 00 00 02 D4 CF
				15 01 00 00 00 00 02 D5 02
				15 01 00 00 00 00 02 D6 FE
				15 01 00 00 00 00 02 D7 03
				15 01 00 00 00 00 02 D8 1C
				15 01 00 00 00 00 02 D9 03
				15 01 00 00 00 00 02 DA 45
				15 01 00 00 00 00 02 DB 03
				15 01 00 00 00 00 02 DC 51
				15 01 00 00 00 00 02 DD 03
				15 01 00 00 00 00 02 DE 5F
				15 01 00 00 00 00 02 DF 03
				15 01 00 00 00 00 02 E0 6F
				15 01 00 00 00 00 02 E1 03
				15 01 00 00 00 00 02 E2 81
				15 01 00 00 00 00 02 E3 03
				15 01 00 00 00 00 02 E4 97
				15 01 00 00 00 00 02 E5 03
				15 01 00 00 00 00 02 E6 AE
				15 01 00 00 00 00 02 E7 03
				15 01 00 00 00 00 02 E8 CB
				15 01 00 00 00 00 02 E9 03
				15 01 00 00 00 00 02 EA D1
				15 01 00 00 00 00 02 FF 00
				05 01 00 00 96 00 01 11
				15 01 00 00 00 00 02 D3 05];
		qcom,mdss-dsi-on-command = [05 01 00 00 00 00 01 29];
		qcom,mdss-dsi-off-command = [05 01 00 00 14 00 01 28
				05 01 00 00 64 00 01 10];
		qcom,mdss-dsi-on-command-state = "dsi_lp_mode";
		qcom,mdss-dsi-off-command-state = "dsi_hs_mode";

		somc,mdss-dsi-cabc-early-on-command = [39 01 00 00 00 00 03 51 0F FF
				15 01 00 00 00 00 02 53 24
				15 01 00 00 00 00 02 55 02];
		somc,mdss-dsi-cabc-late-off-command = [39 01 00 00 00 00 03 51 00 00
				15 01 00 00 00 00 02 55 00
				15 01 00 00 00 00 02 53 20];
		somc,mdss-dsi-cabc-enabled = <0>;

		qcom,mdss-dsi-h-sync-pulse = <1>;
		qcom,mdss-dsi-traffic-mode = "non_burst_sync_event";
		qcom,mdss-dsi-bllp-eof-power-mode;
		qcom,mdss-dsi-bllp-power-mode;
		qcom,mdss-dsi-lane-0-state;
		qcom,mdss-dsi-lane-1-state;
		qcom,mdss-dsi-lane-2-state;
		qcom,mdss-dsi-lane-3-state;
		qcom,mdss-dsi-panel-timings = [E6 38 26 00 68 6C 2A 3A 2C 03 04 00];
		qcom,mdss-dsi-lp11-init;
		qcom,mdss-dsi-t-clk-post = <0x02>;
		qcom,mdss-dsi-t-clk-pre = <0x2B>;
		qcom,mdss-dsi-bl-min-level = <1>;
		qcom,mdss-dsi-bl-max-level = <4095>;
		qcom,mdss-brightness-max-level = <4095>;
		qcom,mdss-dsi-dma-trigger = "trigger_sw";
		qcom,mdss-dsi-mdp-trigger = "none";
		qcom,mdss-dsi-bl-pmic-control-type = "bl_ctrl_wled";
		qcom,mdss-dsi-pan-enable-dynamic-fps;
		qcom,mdss-dsi-pan-fps-update = "dfps_suspend_resume_mode";
		qcom,cont-splash-enabled;

		somc,driver-ic = <1>;
		somc,dric-gpio = <&msmgpio 26 0>;
		somc,mul-channel-scaling = <3>;
		somc,mdss-phy-size-mm = <64 114>;
		somc,mdss-dsi-lane-config = [00 c2 ef 00 00 00 00 01 75
				00 c2 ef 00 00 00 00 01 75
				00 c2 ef 00 00 00 00 01 75
				00 c2 ef 00 00 00 00 01 75
				00 02 45 00 00 00 00 01 97];
		somc,mdss-dsi-disp-on-in-hs = <1>;
		somc,lcd-id = <1>;
		somc,lcd-id-adc = <1236000 1395000>;
		somc,disp-en-on-pre = <25>;
		somc,pw-on-rst-seq = <0 60>, <1 10>;
		somc,disp-en-off-post = <50>;
		somc,pw-off-rst-b-seq = <0 10>;

		somc,mdss-dsi-pre-uv-command = [15 01 00 00 00 00 02 FF 00];
		somc,mdss-dsi-uv-command = [06 01 00 00 00 00 01 DA
					06 01 00 00 00 00 01 DB];
		somc,mdss-dsi-uv-param-type = <2>;
		somc,mdss-dsi-pcc-table-size = <73>;
		somc,mdss-dsi-pcc-table = <
			0x00 0x01 0x10 0x13 0x28 0x2B 0x8000 0x7400 0x8000
			0x00 0x02 0x14 0x17 0x28 0x2B 0x7a80 0x7400 0x7e00
			0x00 0x03 0x18 0x1B 0x28 0x2B 0x7480 0x7380 0x8000
			0x00 0x04 0x1C 0x1F 0x28 0x2B 0x7280 0x7380 0x8000
			0x00 0x05 0x20 0x23 0x28 0x2B 0x6e00 0x7400 0x8000
			0x00 0x06 0x0C 0x0F 0x24 0x27 0x7f80 0x7200 0x7c00
			0x00 0x07 0x10 0x13 0x24 0x27 0x8000 0x7400 0x7d80
			0x00 0x08 0x14 0x17 0x24 0x27 0x7d00 0x7700 0x7e00
			0x00 0x09 0x18 0x1B 0x24 0x27 0x7700 0x7600 0x8000
			0x00 0x0A 0x1C 0x1F 0x24 0x27 0x7380 0x7500 0x7c00
			0x00 0x0B 0x20 0x23 0x24 0x27 0x6f00 0x7500 0x7e80
			0x00 0x0C 0x0C 0x0F 0x20 0x23 0x7f80 0x7200 0x7900
			0x00 0x0D 0x10 0x13 0x20 0x23 0x8000 0x7400 0x7b00
			0x00 0x0E 0x14 0x17 0x20 0x23 0x7a80 0x7400 0x7b00
			0x00 0x0F 0x18 0x1B 0x20 0x23 0x7800 0x7700 0x7e80
			0x00 0x10 0x1C 0x1F 0x20 0x23 0x7780 0x7900 0x7f80
			0x00 0x11 0x20 0x23 0x20 0x23 0x7300 0x7900 0x7f00
			0x00 0x12 0x24 0x27 0x20 0x23 0x7100 0x7980 0x8000
			0x00 0x13 0x0C 0x0F 0x1C 0x1F 0x7f80 0x7200 0x7700
			0x00 0x14 0x10 0x13 0x1C 0x1F 0x7c00 0x7000 0x7580
			0x00 0x15 0x14 0x17 0x1C 0x1F 0x7f80 0x7900 0x7e00
			0x00 0x16 0x18 0x1B 0x1C 0x1F 0x7c00 0x7a00 0x7d80
			0x00 0x17 0x1C 0x1F 0x1C 0x1F 0x7900 0x7a00 0x7e00
			0x00 0x18 0x20 0x23 0x1C 0x1F 0x7600 0x7c80 0x8000
			0x00 0x19 0x24 0x27 0x1C 0x1F 0x7300 0x7c00 0x7e80
			0x00 0x1A 0x0C 0x0F 0x18 0x1B 0x8000 0x7200 0x7300
			0x00 0x1B 0x10 0x13 0x18 0x1B 0x7e80 0x7200 0x7500
			0x00 0x1C 0x14 0x17 0x18 0x1B 0x7f00 0x7900 0x7b80
			0x00 0x1D 0x18 0x1B 0x18 0x1B 0x7f00 0x7d00 0x7e00
			0x00 0x1E 0x1C 0x1F 0x18 0x1B 0x7d00 0x7d80 0x8000
			0x00 0x1F 0x20 0x23 0x18 0x1B 0x7900 0x7f00 0x8000
			0x00 0x20 0x24 0x27 0x18 0x1B 0x7780 0x8000 0x8000
			0x00 0x21 0x10 0x13 0x14 0x17 0x7f80 0x7380 0x7200
			0x00 0x22 0x14 0x17 0x14 0x17 0x7f00 0x7900 0x7900
			0x00 0x23 0x18 0x1B 0x14 0x17 0x7f00 0x7d00 0x7b80
			0xFF 0x00 0x1C 0x1F 0x14 0x17 0x8000 0x8000 0x8000
			0x00 0x24 0x20 0x23 0x14 0x17 0x7a00 0x8000 0x7e80
			0x00 0x25 0x24 0x27 0x14 0x17 0x7780 0x8000 0x7d80
			0x00 0x26 0x10 0x13 0x10 0x13 0x8000 0x7400 0x7000
			0x00 0x27 0x14 0x17 0x10 0x13 0x7f80 0x7900 0x7680
			0x00 0x28 0x18 0x1B 0x10 0x13 0x8000 0x7d80 0x7980
			0x00 0x29 0x1C 0x1F 0x10 0x13 0x8000 0x8000 0x7c00
			0x00 0x2A 0x20 0x23 0x10 0x13 0x7a00 0x8000 0x7c00
			0x00 0x2B 0x10 0x13 0x0C 0x0F 0x7f80 0x7480 0x6f00
			0x00 0x2C 0x14 0x17 0x0C 0x0F 0x7f80 0x7900 0x7400
			0x00 0x2D 0x18 0x1B 0x0C 0x0F 0x7f80 0x7d80 0x7680
			0x00 0x2E 0x1C 0x1F 0x0C 0x0F 0x8000 0x8000 0x7980
			0x01 0x00 0x00 0x09 0x32 0x3B 0x8000 0x6D00 0x8000
			0x02 0x00 0x0A 0x13 0x32 0x3B 0x7A00 0x7100 0x8000
			0x03 0x00 0x14 0x1D 0x32 0x3B 0x7400 0x7180 0x8000
			0x04 0x00 0x1E 0x27 0x32 0x3B 0x7100 0x7200 0x8000
			0x05 0x00 0x28 0x31 0x32 0x3B 0x6C80 0x7180 0x8000
			0x06 0x00 0x32 0x3B 0x32 0x3B 0x6680 0x7300 0x8000
			0x07 0x00 0x00 0x09 0x28 0x31 0x8000 0x6B80 0x7080
			0x08 0x00 0x0A 0x13 0x28 0x31 0x8000 0x7400 0x8000
			0x09 0x00 0x14 0x1D 0x28 0x31 0x7A00 0x7700 0x8000
			0x0A 0x00 0x1E 0x27 0x28 0x31 0x7600 0x7780 0x8000
			0x0B 0x00 0x28 0x31 0x28 0x31 0x6F80 0x7980 0x8000
			0x0C 0x00 0x32 0x3B 0x28 0x31 0x7080 0x7E80 0x8000
			0x0D 0x00 0x00 0x09 0x14 0x27 0x8000 0x6B00 0x6D00
			0x0E 0x00 0x0A 0x13 0x14 0x27 0x8000 0x7380 0x7480
			0xFF 0x00 0x14 0x27 0x14 0x27 0x8000 0x8000 0x8000
			0x10 0x00 0x28 0x31 0x14 0x27 0x7500 0x8000 0x7E80
			0x11 0x00 0x32 0x3B 0x14 0x27 0x7100 0x8000 0x7C80
			0x12 0x00 0x00 0x09 0x00 0x09 0x8000 0x6900 0x6500
			0x13 0x00 0x00 0x13 0x0A 0x13 0x8000 0x7300 0x6F00
			0x13 0x00 0x0A 0x13 0x00 0x09 0x8000 0x7300 0x6F00
			0x14 0x00 0x14 0x27 0x0A 0x13 0x7F00 0x8000 0x7900
			0x15 0x00 0x14 0x27 0x00 0x09 0x7E80 0x8000 0x7680
			0x16 0x00 0x28 0x31 0x0A 0x13 0x7380 0x8000 0x7600
			0x17 0x00 0x32 0x3B 0x0A 0x13 0x7080 0x8000 0x7900
			0x18 0x00 0x28 0x31 0x00 0x09 0x7A00 0x8000 0x7580
			0x19 0x00 0x32 0x3B 0x00 0x09 0x6F00 0x8000 0x7200>;
	};

	dsi_novatek_auo_1080_vid: somc,novatek_auo_1080p_panel {
		qcom,mdss-dsi-panel-name = "auo novatek 1080p video";
		qcom,mdss-dsi-panel-controller = <&mdss_dsi0>;
		qcom,mdss-dsi-panel-type = "dsi_video_mode";
		qcom,mdss-dsi-panel-destination = "display_1";
		qcom,mdss-dsi-panel-framerate = <60>;
		qcom,mdss-dsi-virtual-channel-id = <0>;
		qcom,mdss-dsi-stream = <0>;
		qcom,mdss-dsi-panel-width = <1080>;
		qcom,mdss-dsi-panel-height = <1920>;
		qcom,mdss-dsi-h-front-porch = <104>;
		qcom,mdss-dsi-h-back-porch = <56>;
		qcom,mdss-dsi-h-pulse-width = <20>;
		qcom,mdss-dsi-h-sync-skew = <0>;
		qcom,mdss-dsi-v-back-porch = <46>;
		qcom,mdss-dsi-v-front-porch = <6>;
		qcom,mdss-dsi-v-pulse-width = <2>;
		qcom,mdss-dsi-h-left-border = <0>;
		qcom,mdss-dsi-h-right-border = <0>;
		qcom,mdss-dsi-v-top-border = <0>;
		qcom,mdss-dsi-v-bottom-border = <0>;
		qcom,mdss-dsi-bpp = <24>;
		qcom,mdss-dsi-underflow-color = <0x0>;
		qcom,mdss-dsi-border-color = <0>;
		somc,mdss-dsi-init-command = [15 01 00 00 00 00 02 FF 05
				15 01 00 00 00 00 02 FB 01
				15 01 00 00 00 00 02 93 06
				15 01 00 00 00 00 02 94 30
				15 01 00 00 00 00 02 FF 00
				15 01 00 00 00 00 02 FF 01
				15 01 00 00 00 00 02 01 55
				15 01 00 00 00 00 02 15 0F
				15 01 00 00 00 00 02 16 0F
				15 01 00 00 00 00 02 1B 1B
				15 01 00 00 00 00 02 1C F7
				15 01 00 00 00 00 02 60 0F
				15 01 00 00 00 00 02 58 82
				15 01 00 00 00 00 02 59 00
				15 01 00 00 00 00 02 5A 02
				15 01 00 00 00 00 02 5B 00
				15 01 00 00 00 00 02 5C 82
				15 01 00 00 00 00 02 5D 80
				15 01 00 00 00 00 02 5E 02
				15 01 00 00 00 00 02 5F 00
				15 01 00 00 00 00 02 66 01
				15 01 00 00 00 00 02 FB 01
				15 01 00 00 00 00 02 FF 05
				15 01 00 00 00 00 02 54 75
				15 01 00 00 00 00 02 85 05
				15 01 00 00 00 00 02 A6 04
				15 01 00 00 00 00 02 FB 01
				15 01 00 00 00 00 02 FF FF
				15 01 00 00 00 00 02 4F 03
				15 01 00 00 00 00 02 FB 01
				15 01 00 00 00 00 02 FF 00
				15 01 00 00 00 00 02 35 01
				15 01 00 00 00 00 02 D3 30
				15 01 00 00 00 00 02 D4 06
				05 01 00 00 64 00 01 11];
		qcom,mdss-dsi-on-command = [05 01 00 00 64 00 01 29];
		qcom,mdss-dsi-off-command = [05 01 00 00 14 00 01 28
				05 01 00 00 64 00 01 10];
		qcom,mdss-dsi-on-command-state = "dsi_lp_mode";
		qcom,mdss-dsi-off-command-state = "dsi_hs_mode";

		qcom,mdss-dsi-h-sync-pulse = <1>;
		qcom,mdss-dsi-traffic-mode = "non_burst_sync_event";
		qcom,mdss-dsi-bllp-eof-power-mode;
		qcom,mdss-dsi-bllp-power-mode;
		qcom,mdss-dsi-lane-0-state;
		qcom,mdss-dsi-lane-1-state;
		qcom,mdss-dsi-lane-2-state;
		qcom,mdss-dsi-lane-3-state;
		qcom,mdss-dsi-panel-timings = [E6 38 26 00 68 6C 2A 3C 2C 03 04 00];
		qcom,mdss-dsi-lp11-init;
		qcom,mdss-dsi-t-clk-post = <0x02>;
		qcom,mdss-dsi-t-clk-pre = <0x2B>;
		qcom,mdss-dsi-bl-min-level = <1>;
		qcom,mdss-dsi-bl-max-level = <4095>;
		qcom,mdss-brightness-max-level = <4095>;
		qcom,mdss-dsi-dma-trigger = "trigger_sw";
		qcom,mdss-dsi-mdp-trigger = "none";
		qcom,mdss-dsi-bl-pmic-control-type = "bl_ctrl_wled";
		qcom,mdss-dsi-pan-enable-dynamic-fps;
		qcom,mdss-dsi-pan-fps-update = "dfps_suspend_resume_mode";
		qcom,cont-splash-enabled;

		somc,driver-ic = <1>;
		somc,dric-gpio = <&msmgpio 26 0>;
		somc,mul-channel-scaling = <3>;
		somc,mdss-phy-size-mm = <64 114>;
		somc,mdss-dsi-lane-config = [00 c2 ef 00 00 00 00 01 75
				00 c2 ef 00 00 00 00 01 75
				00 c2 ef 00 00 00 00 01 75
				00 c2 ef 00 00 00 00 01 75
				00 02 45 00 00 00 00 01 97];
		somc,mdss-dsi-disp-on-in-hs = <1>;
		somc,lcd-id = <1>;
		somc,lcd-id-adc = <1420000 1594000>;
		somc,disp-en-on-post = <20>;
		somc,disp-en-off-post = <70>;
		somc,pw-on-rst-seq = <1 10>;
		somc,pw-off-rst-seq = <0 0>;

		somc,mdss-dsi-pre-uv-command = [15 01 00 00 00 00 02 FF 00];
		somc,mdss-dsi-uv-command = [06 01 00 00 00 00 01 DA
					06 01 00 00 00 00 01 DC];
		somc,mdss-dsi-uv-param-type = <2>;
		somc,mdss-dsi-pcc-table-size = <73>;
		somc,mdss-dsi-pcc-table = <
			0x00 0x01 0x10 0x13 0x28 0x2B 0x8000 0x7400 0x8000
			0x00 0x02 0x14 0x17 0x28 0x2B 0x7a80 0x7400 0x7e00
			0x00 0x03 0x18 0x1B 0x28 0x2B 0x7480 0x7380 0x8000
			0x00 0x04 0x1C 0x1F 0x28 0x2B 0x7280 0x7380 0x8000
			0x00 0x05 0x20 0x23 0x28 0x2B 0x6e00 0x7400 0x8000
			0x00 0x06 0x0C 0x0F 0x24 0x27 0x7f80 0x7200 0x7c00
			0x00 0x07 0x10 0x13 0x24 0x27 0x8000 0x7400 0x7d80
			0x00 0x08 0x14 0x17 0x24 0x27 0x7d00 0x7700 0x7e00
			0x00 0x09 0x18 0x1B 0x24 0x27 0x7700 0x7600 0x8000
			0x00 0x0A 0x1C 0x1F 0x24 0x27 0x7380 0x7500 0x7c00
			0x00 0x0B 0x20 0x23 0x24 0x27 0x6f00 0x7500 0x7e80
			0x00 0x0C 0x0C 0x0F 0x20 0x23 0x7f80 0x7200 0x7900
			0x00 0x0D 0x10 0x13 0x20 0x23 0x8000 0x7400 0x7b00
			0x00 0x0E 0x14 0x17 0x20 0x23 0x7a80 0x7400 0x7b00
			0x00 0x0F 0x18 0x1B 0x20 0x23 0x7800 0x7700 0x7e80
			0x00 0x10 0x1C 0x1F 0x20 0x23 0x7780 0x7900 0x7f80
			0x00 0x11 0x20 0x23 0x20 0x23 0x7300 0x7900 0x7f00
			0x00 0x12 0x24 0x27 0x20 0x23 0x7100 0x7980 0x8000
			0x00 0x13 0x0C 0x0F 0x1C 0x1F 0x7f80 0x7200 0x7700
			0x00 0x14 0x10 0x13 0x1C 0x1F 0x7c00 0x7000 0x7580
			0x00 0x15 0x14 0x17 0x1C 0x1F 0x7f80 0x7900 0x7e00
			0x00 0x16 0x18 0x1B 0x1C 0x1F 0x7c00 0x7a00 0x7d80
			0x00 0x17 0x1C 0x1F 0x1C 0x1F 0x7900 0x7a00 0x7e00
			0x00 0x18 0x20 0x23 0x1C 0x1F 0x7600 0x7c80 0x8000
			0x00 0x19 0x24 0x27 0x1C 0x1F 0x7300 0x7c00 0x7e80
			0x00 0x1A 0x0C 0x0F 0x18 0x1B 0x8000 0x7200 0x7300
			0x00 0x1B 0x10 0x13 0x18 0x1B 0x7e80 0x7200 0x7500
			0x00 0x1C 0x14 0x17 0x18 0x1B 0x7f00 0x7900 0x7b80
			0x00 0x1D 0x18 0x1B 0x18 0x1B 0x7f00 0x7d00 0x7e00
			0x00 0x1E 0x1C 0x1F 0x18 0x1B 0x7d00 0x7d80 0x8000
			0x00 0x1F 0x20 0x23 0x18 0x1B 0x7900 0x7f00 0x8000
			0x00 0x20 0x24 0x27 0x18 0x1B 0x7780 0x8000 0x8000
			0x00 0x21 0x10 0x13 0x14 0x17 0x7f80 0x7380 0x7200
			0x00 0x22 0x14 0x17 0x14 0x17 0x7f00 0x7900 0x7900
			0x00 0x23 0x18 0x1B 0x14 0x17 0x7f00 0x7d00 0x7b80
			0xFF 0x00 0x1C 0x1F 0x14 0x17 0x8000 0x8000 0x8000
			0x00 0x24 0x20 0x23 0x14 0x17 0x7a00 0x8000 0x7e80
			0x00 0x25 0x24 0x27 0x14 0x17 0x7780 0x8000 0x7d80
			0x00 0x26 0x10 0x13 0x10 0x13 0x8000 0x7400 0x7000
			0x00 0x27 0x14 0x17 0x10 0x13 0x7f80 0x7900 0x7680
			0x00 0x28 0x18 0x1B 0x10 0x13 0x8000 0x7d80 0x7980
			0x00 0x29 0x1C 0x1F 0x10 0x13 0x8000 0x8000 0x7c00
			0x00 0x2A 0x20 0x23 0x10 0x13 0x7a00 0x8000 0x7c00
			0x00 0x2B 0x10 0x13 0x0C 0x0F 0x7f80 0x7480 0x6f00
			0x00 0x2C 0x14 0x17 0x0C 0x0F 0x7f80 0x7900 0x7400
			0x00 0x2D 0x18 0x1B 0x0C 0x0F 0x7f80 0x7d80 0x7680
			0x00 0x2E 0x1C 0x1F 0x0C 0x0F 0x8000 0x8000 0x7980
			0x01 0x00 0x00 0x09 0x32 0x3B 0x8000 0x6D00 0x8000
			0x02 0x00 0x0A 0x13 0x32 0x3B 0x7A00 0x7100 0x8000
			0x03 0x00 0x14 0x1D 0x32 0x3B 0x7400 0x7180 0x8000
			0x04 0x00 0x1E 0x27 0x32 0x3B 0x7100 0x7200 0x8000
			0x05 0x00 0x28 0x31 0x32 0x3B 0x6C80 0x7180 0x8000
			0x06 0x00 0x32 0x3B 0x32 0x3B 0x6680 0x7300 0x8000
			0x07 0x00 0x00 0x09 0x28 0x31 0x8000 0x6B80 0x7080
			0x08 0x00 0x0A 0x13 0x28 0x31 0x8000 0x7400 0x8000
			0x09 0x00 0x14 0x1D 0x28 0x31 0x7A00 0x7700 0x8000
			0x0A 0x00 0x1E 0x27 0x28 0x31 0x7600 0x7780 0x8000
			0x0B 0x00 0x28 0x31 0x28 0x31 0x6F80 0x7980 0x8000
			0x0C 0x00 0x32 0x3B 0x28 0x31 0x7080 0x7E80 0x8000
			0x0D 0x00 0x00 0x09 0x14 0x27 0x8000 0x6B00 0x6D00
			0x0E 0x00 0x0A 0x13 0x14 0x27 0x8000 0x7380 0x7480
			0xFF 0x00 0x14 0x27 0x14 0x27 0x8000 0x8000 0x8000
			0x10 0x00 0x28 0x31 0x14 0x27 0x7500 0x8000 0x7E80
			0x11 0x00 0x32 0x3B 0x14 0x27 0x7100 0x8000 0x7C80
			0x12 0x00 0x00 0x09 0x00 0x09 0x8000 0x6900 0x6500
			0x13 0x00 0x00 0x13 0x0A 0x13 0x8000 0x7300 0x6F00
			0x13 0x00 0x0A 0x13 0x00 0x09 0x8000 0x7300 0x6F00
			0x14 0x00 0x14 0x27 0x0A 0x13 0x7F00 0x8000 0x7900
			0x15 0x00 0x14 0x27 0x00 0x09 0x7E80 0x8000 0x7680
			0x16 0x00 0x28 0x31 0x0A 0x13 0x7380 0x8000 0x7600
			0x17 0x00 0x32 0x3B 0x0A 0x13 0x7080 0x8000 0x7900
			0x18 0x00 0x28 0x31 0x00 0x09 0x7A00 0x8000 0x7580
			0x19 0x00 0x32 0x3B 0x00 0x09 0x6F00 0x8000 0x7200>;
	};

	dsi_default_gpio_0: somc,default_panel_0 {
		qcom,mdss-dsi-panel-name = "default renesas video";
		qcom,mdss-dsi-panel-controller = <&mdss_dsi0>;
		qcom,mdss-dsi-panel-type = "dsi_video_mode";
		qcom,mdss-dsi-panel-destination = "display_1";
		qcom,mdss-dsi-panel-framerate = <60>;
		qcom,mdss-dsi-virtual-channel-id = <0>;
		qcom,mdss-dsi-stream = <0>;
		qcom,mdss-dsi-panel-width = <1080>;
		qcom,mdss-dsi-panel-height = <1920>;
		qcom,mdss-dsi-h-front-porch = <128>;
		qcom,mdss-dsi-h-back-porch = <76>;
		qcom,mdss-dsi-h-pulse-width = <4>;
		qcom,mdss-dsi-h-sync-skew = <0>;
		qcom,mdss-dsi-v-back-porch = <3>;
		qcom,mdss-dsi-v-front-porch = <4>;
		qcom,mdss-dsi-v-pulse-width = <2>;
		qcom,mdss-dsi-h-left-border = <0>;
		qcom,mdss-dsi-h-right-border = <0>;
		qcom,mdss-dsi-v-top-border = <0>;
		qcom,mdss-dsi-v-bottom-border = <0>;
		qcom,mdss-dsi-bpp = <24>;
		qcom,mdss-dsi-underflow-color = <0x0>;
		qcom,mdss-dsi-border-color = <0>;
		somc,mdss-dsi-init-command = [23 01 00 00 00 00 02 B0 04
				23 01 00 00 00 00 02 00 00
				23 01 00 00 00 00 02 00 00
				23 01 00 00 00 00 02 D6 01
				29 01 00 00 00 00 03 C0 0F 0F
				29 01 00 00 00 00 03 EC 00 10
				29 01 00 00 00 00 19 C7
					05 19 22 2B 38 51 41 50 5C 64 6B 74
					0F 23 2B 32 3F 52 44 55 61 69 70 77
				29 01 00 00 00 00 19 C8
					03 18 21 2B 38 51 42 4F 5D 65 6C 74
					0D 22 2A 32 3E 52 41 54 5D 66 6D 77
				29 01 00 00 00 00 19 C9
					00 15 1E 28 36 50 42 50 5E 66 6D 74
					0A 1F 27 2F 3D 51 41 55 5E 67 6E 77
				05 01 00 00 00 00 01 11];
		qcom,mdss-dsi-on-command = [05 01 00 00 00 00 01 29];
		qcom,mdss-dsi-off-command = [05 01 00 00 14 00 01 28
				05 01 00 00 6E 00 01 10];
		qcom,mdss-dsi-on-command-state = "dsi_lp_mode";
		qcom,mdss-dsi-off-command-state = "dsi_hs_mode";

		somc,mdss-dsi-cabc-early-on-command = [39 01 00 00 00 00 03 51 0F FF
				15 01 00 00 00 00 02 53 24
				15 01 00 00 00 00 02 55 02];
		somc,mdss-dsi-cabc-late-off-command = [39 01 00 00 00 00 03 51 00 00
				15 01 00 00 00 00 02 55 00
				15 01 00 00 00 00 02 53 20];
		somc,mdss-dsi-cabc-enabled = <0>;

		qcom,mdss-dsi-h-sync-pulse = <1>;
		qcom,mdss-dsi-traffic-mode = "non_burst_sync_event";
		qcom,mdss-dsi-bllp-eof-power-mode;
		qcom,mdss-dsi-bllp-power-mode;
		qcom,mdss-dsi-lane-0-state;
		qcom,mdss-dsi-lane-1-state;
		qcom,mdss-dsi-lane-2-state;
		qcom,mdss-dsi-lane-3-state;
		qcom,mdss-dsi-panel-timings = [E6 38 26 00 68 6C 2A 3A 2C 03 04 00];
		qcom,mdss-dsi-lp11-init;
		qcom,mdss-dsi-t-clk-post = <0x02>;
		qcom,mdss-dsi-t-clk-pre = <0x2B>;
		qcom,mdss-dsi-bl-min-level = <1>;
		qcom,mdss-dsi-bl-max-level = <4095>;
		qcom,mdss-brightness-max-level = <4095>;
		qcom,mdss-dsi-dma-trigger = "trigger_sw";
		qcom,mdss-dsi-mdp-trigger = "none";
		qcom,mdss-dsi-bl-pmic-control-type = "bl_ctrl_wled";
		qcom,mdss-dsi-pan-enable-dynamic-fps;
		qcom,mdss-dsi-pan-fps-update = "dfps_suspend_resume_mode";
		qcom,cont-splash-enabled;

		somc,driver-ic = <0>;
		somc,dric-gpio = <&msmgpio 26 0>;
		somc,mul-channel-scaling = <3>;
		somc,mdss-phy-size-mm = <64 114>;
		somc,mdss-dsi-lane-config = [00 c2 ef 00 00 00 00 01 75
				00 c2 ef 00 00 00 00 01 75
				00 c2 ef 00 00 00 00 01 75
				00 c2 ef 00 00 00 00 01 75
				00 02 45 00 00 00 00 01 97];
		somc,mdss-dsi-disp-on-in-hs = <1>;
		somc,mdss-dsi-wait-time-before-on-cmd = <150>;
		somc,lcd-id = <0>;
		somc,lcd-id-adc = <0 0x7fffffff>;
		somc,disp-en-on-pre = <25>;
		somc,pw-on-rst-seq = <0 60>, <1 10>;
		somc,disp-en-off-post = <50>;
		somc,pw-off-rst-b-seq = <0 10>;
	};

	dsi_default_gpio_1: somc,default_panel_1 {
		qcom,mdss-dsi-panel-name = "default renesas video";
		qcom,mdss-dsi-panel-controller = <&mdss_dsi0>;
		qcom,mdss-dsi-panel-type = "dsi_video_mode";
		qcom,mdss-dsi-panel-destination = "display_1";
		qcom,mdss-dsi-panel-framerate = <60>;
		qcom,mdss-dsi-virtual-channel-id = <0>;
		qcom,mdss-dsi-stream = <0>;
		qcom,mdss-dsi-panel-width = <1080>;
		qcom,mdss-dsi-panel-height = <1920>;
		qcom,mdss-dsi-h-front-porch = <128>;
		qcom,mdss-dsi-h-back-porch = <76>;
		qcom,mdss-dsi-h-pulse-width = <4>;
		qcom,mdss-dsi-h-sync-skew = <0>;
		qcom,mdss-dsi-v-back-porch = <3>;
		qcom,mdss-dsi-v-front-porch = <4>;
		qcom,mdss-dsi-v-pulse-width = <2>;
		qcom,mdss-dsi-h-left-border = <0>;
		qcom,mdss-dsi-h-right-border = <0>;
		qcom,mdss-dsi-v-top-border = <0>;
		qcom,mdss-dsi-v-bottom-border = <0>;
		qcom,mdss-dsi-bpp = <24>;
		qcom,mdss-dsi-underflow-color = <0x0>;
		qcom,mdss-dsi-border-color = <0>;
		somc,mdss-dsi-init-command = [23 01 00 00 00 00 02 B0 04
				23 01 00 00 00 00 02 00 00
				23 01 00 00 00 00 02 00 00
				23 01 00 00 00 00 02 D6 01
				29 01 00 00 00 00 03 C0 0F 0F
				29 01 00 00 00 00 03 EC 00 10
				29 01 00 00 00 00 19 C7
					05 19 22 2B 38 51 41 50 5C 64 6B 74
					0F 23 2B 32 3F 52 44 55 61 69 70 77
				29 01 00 00 00 00 19 C8
					03 18 21 2B 38 51 42 4F 5D 65 6C 74
					0D 22 2A 32 3E 52 41 54 5D 66 6D 77
				29 01 00 00 00 00 19 C9
					00 15 1E 28 36 50 42 50 5E 66 6D 74
					0A 1F 27 2F 3D 51 41 55 5E 67 6E 77
				05 01 00 00 00 00 01 11];
		qcom,mdss-dsi-on-command = [05 01 00 00 00 00 01 29];
		qcom,mdss-dsi-off-command = [05 01 00 00 14 00 01 28
				05 01 00 00 6E 00 01 10];
		qcom,mdss-dsi-on-command-state = "dsi_lp_mode";
		qcom,mdss-dsi-off-command-state = "dsi_hs_mode";

		somc,mdss-dsi-cabc-early-on-command = [39 01 00 00 00 00 03 51 0F FF
				15 01 00 00 00 00 02 53 24
				15 01 00 00 00 00 02 55 02];
		somc,mdss-dsi-cabc-late-off-command = [39 01 00 00 00 00 03 51 00 00
				15 01 00 00 00 00 02 55 00
				15 01 00 00 00 00 02 53 20];
		somc,mdss-dsi-cabc-enabled = <0>;

		qcom,mdss-dsi-h-sync-pulse = <1>;
		qcom,mdss-dsi-traffic-mode = "non_burst_sync_event";
		qcom,mdss-dsi-bllp-eof-power-mode;
		qcom,mdss-dsi-bllp-power-mode;
		qcom,mdss-dsi-lane-0-state;
		qcom,mdss-dsi-lane-1-state;
		qcom,mdss-dsi-lane-2-state;
		qcom,mdss-dsi-lane-3-state;
		qcom,mdss-dsi-panel-timings = [E6 38 26 00 68 6C 2A 3A 2C 03 04 00];
		qcom,mdss-dsi-lp11-init;
		qcom,mdss-dsi-t-clk-post = <0x02>;
		qcom,mdss-dsi-t-clk-pre = <0x2B>;
		qcom,mdss-dsi-bl-min-level = <1>;
		qcom,mdss-dsi-bl-max-level = <4095>;
		qcom,mdss-brightness-max-level = <4095>;
		qcom,mdss-dsi-dma-trigger = "trigger_sw";
		qcom,mdss-dsi-mdp-trigger = "none";
		qcom,mdss-dsi-bl-pmic-control-type = "bl_ctrl_wled";
		qcom,mdss-dsi-pan-enable-dynamic-fps;
		qcom,mdss-dsi-pan-fps-update = "dfps_suspend_resume_mode";
		qcom,cont-splash-enabled;

		somc,driver-ic = <0>;
		somc,dric-gpio = <&msmgpio 26 0>;
		somc,mul-channel-scaling = <3>;
		somc,mdss-phy-size-mm = <64 114>;
		somc,mdss-dsi-lane-config = [00 c2 ef 00 00 00 00 01 75
				00 c2 ef 00 00 00 00 01 75
				00 c2 ef 00 00 00 00 01 75
				00 c2 ef 00 00 00 00 01 75
				00 02 45 00 00 00 00 01 97];
		somc,mdss-dsi-disp-on-in-hs = <1>;
		somc,mdss-dsi-wait-time-before-on-cmd = <150>;
		somc,lcd-id = <1>;
		somc,lcd-id-adc = <0 0x7fffffff>;
		somc,disp-en-on-pre = <25>;
		somc,pw-on-rst-seq = <0 60>, <1 10>;
		somc,disp-en-off-post = <50>;
		somc,pw-off-rst-b-seq = <0 10>;
	};
};
